VERSION ""

NS_ :

BS_:

BU_: ADAS MINIEYE_TRANSMITTER

BO_ 3221225472 VECTOR__INDEPENDENT_SIG_MSG: 0 Vector__XXX
 SG_ Lane1_CanMsgEnd : 0|1@1+ (1,0) [0|1] "" Vector__XXX
 SG_ Lane2_CanMsgEnd : 0|1@1+ (1,0) [0|1] "" Vector__XXX
 SG_ Lane3_CanMsgEnd : 0|1@1+ (1,0) [0|1] "" Vector__XXX
 SG_ Lane4_CanMsgEnd : 0|1@1+ (1,0) [0|1] "" Vector__XXX

BO_ 1056 DebugMessage: 8 Vector__XXX
 SG_ Speed : 40|8@1+ (1,0) [0|255] "km/h" Vector__XXX
 SG_ Counter : 32|8@1+ (1,0) [0|255] "" Vector__XXX
 SG_ FrameID : 0|32@1+ (1,0) [0|4294967295] "" Vector__XXX

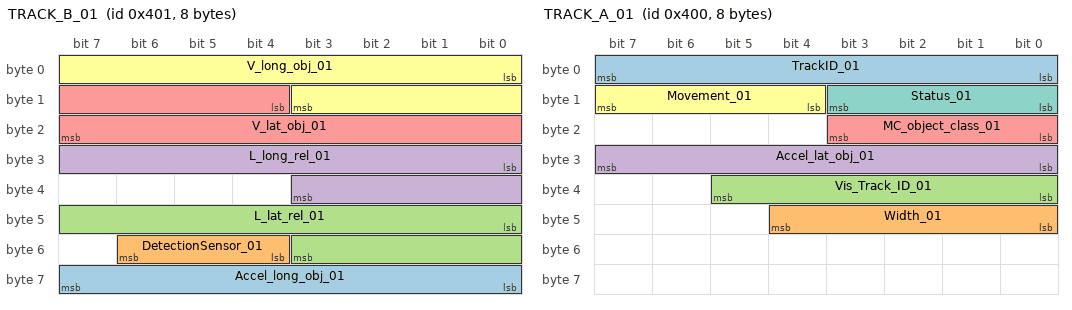
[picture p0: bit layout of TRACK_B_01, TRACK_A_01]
BO_ 1025 TRACK_B_01: 8 MINIEYE_TRANSMITTER
 SG_ Accel_long_obj_01 : 56|8@1- (0.1,0) [-12.5|12.5] "m/s2"  ADAS
 SG_ DetectionSensor_01 : 52|3@1+ (1,0) [0|7] ""  ADAS
 SG_ L_lat_rel_01 : 40|12@1- (0.05,0) [-100|100] "m"  ADAS
 SG_ L_long_rel_01 : 24|12@1- (0.1,0) [0|200] "m"  ADAS
 SG_ V_lat_obj_01 : 12|12@1- (0.1,0) [-50|50] "m/s"  ADAS
 SG_ V_long_obj_01 : 0|12@1- (0.1,0) [-100|100] "m/s"  ADAS

BO_ 1024 TRACK_A_01: 8 MINIEYE_TRANSMITTER
 SG_ TrackID_01 : 0|8@1+ (1,0) [0|63] ""  ADAS
 SG_ Width_01 : 40|5@1+ (0.1,0) [0|3.1] "m"  ADAS
 SG_ Vis_Track_ID_01 : 32|6@1+ (1,0) [0|63] ""  ADAS
 SG_ Accel_lat_obj_01 : 24|8@1- (0.1,0) [-10|10] "m/s2"  ADAS
 SG_ MC_object_class_01 : 16|4@1+ (1,0) [0|10] ""  ADAS
 SG_ Movement_01 : 12|4@1+ (1,0) [0|15] ""  ADAS
 SG_ Status_01 : 8|4@1+ (1,0) [0|7] ""  ADAS

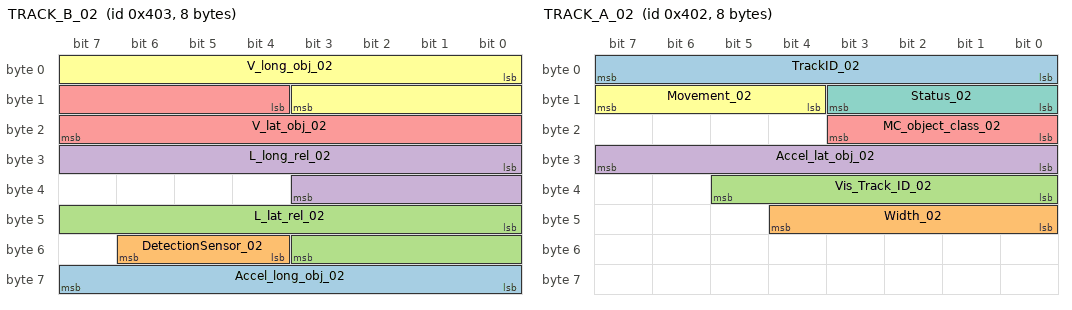
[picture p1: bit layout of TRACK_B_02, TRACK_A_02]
BO_ 1027 TRACK_B_02: 8 MINIEYE_TRANSMITTER
 SG_ Accel_long_obj_02 : 56|8@1- (0.1,0) [-12.5|12.5] "m/s2"  ADAS
 SG_ DetectionSensor_02 : 52|3@1+ (1,0) [0|7] ""  ADAS
 SG_ L_lat_rel_02 : 40|12@1- (0.05,0) [-100|100] "m"  ADAS
 SG_ L_long_rel_02 : 24|12@1- (0.1,0) [0|200] "m"  ADAS
 SG_ V_lat_obj_02 : 12|12@1- (0.1,0) [-50|50] "m/s"  ADAS
 SG_ V_long_obj_02 : 0|12@1- (0.1,0) [-100|100] "m/s"  ADAS

BO_ 1026 TRACK_A_02: 8 MINIEYE_TRANSMITTER
 SG_ TrackID_02 : 0|8@1+ (1,0) [0|63] ""  ADAS
 SG_ Width_02 : 40|5@1+ (0.1,0) [0|3.1] "m"  ADAS
 SG_ Vis_Track_ID_02 : 32|6@1+ (1,0) [0|63] ""  ADAS
 SG_ Accel_lat_obj_02 : 24|8@1- (0.1,0) [-10|10] "m/s2"  ADAS
 SG_ MC_object_class_02 : 16|4@1+ (1,0) [0|10] ""  ADAS
 SG_ Movement_02 : 12|4@1+ (1,0) [0|15] ""  ADAS
 SG_ Status_02 : 8|4@1+ (1,0) [0|7] ""  ADAS

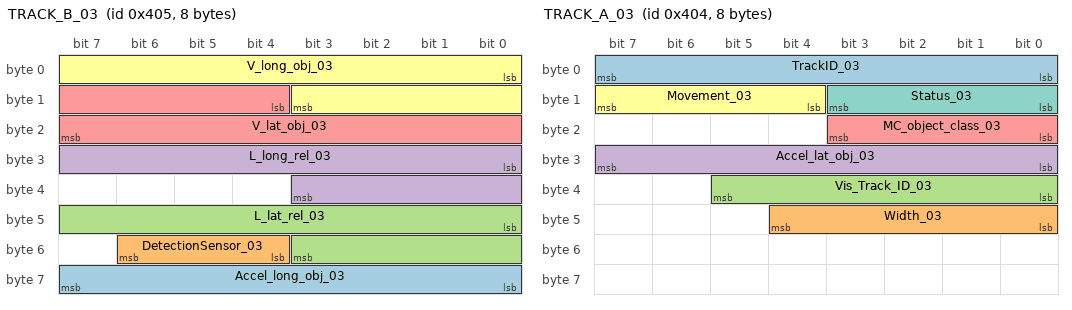
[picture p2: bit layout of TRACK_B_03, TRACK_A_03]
BO_ 1029 TRACK_B_03: 8 MINIEYE_TRANSMITTER
 SG_ Accel_long_obj_03 : 56|8@1- (0.1,0) [-12.5|12.5] "m/s2"  ADAS
 SG_ DetectionSensor_03 : 52|3@1+ (1,0) [0|7] ""  ADAS
 SG_ L_lat_rel_03 : 40|12@1- (0.05,0) [-100|100] "m"  ADAS
 SG_ L_long_rel_03 : 24|12@1- (0.1,0) [0|200] "m"  ADAS
 SG_ V_lat_obj_03 : 12|12@1- (0.1,0) [-50|50] "m/s"  ADAS
 SG_ V_long_obj_03 : 0|12@1- (0.1,0) [-100|100] "m/s"  ADAS

BO_ 1028 TRACK_A_03: 8 MINIEYE_TRANSMITTER
 SG_ TrackID_03 : 0|8@1+ (1,0) [0|63] ""  ADAS
 SG_ Width_03 : 40|5@1+ (0.1,0) [0|3.1] "m"  ADAS
 SG_ Vis_Track_ID_03 : 32|6@1+ (1,0) [0|63] ""  ADAS
 SG_ Accel_lat_obj_03 : 24|8@1- (0.1,0) [-10|10] "m/s2"  ADAS
 SG_ MC_object_class_03 : 16|4@1+ (1,0) [0|10] ""  ADAS
 SG_ Movement_03 : 12|4@1+ (1,0) [0|15] ""  ADAS
 SG_ Status_03 : 8|4@1+ (1,0) [0|7] ""  ADAS

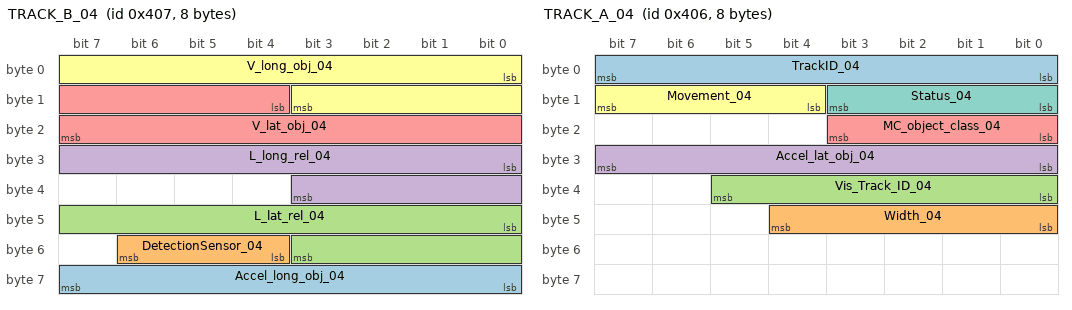
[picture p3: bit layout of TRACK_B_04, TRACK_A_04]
BO_ 1031 TRACK_B_04: 8 MINIEYE_TRANSMITTER
 SG_ Accel_long_obj_04 : 56|8@1- (0.1,0) [-12.5|12.5] "m/s2"  ADAS
 SG_ DetectionSensor_04 : 52|3@1+ (1,0) [0|7] ""  ADAS
 SG_ L_lat_rel_04 : 40|12@1- (0.05,0) [-100|100] "m"  ADAS
 SG_ L_long_rel_04 : 24|12@1- (0.1,0) [0|200] "m"  ADAS
 SG_ V_lat_obj_04 : 12|12@1- (0.1,0) [-50|50] "m/s"  ADAS
 SG_ V_long_obj_04 : 0|12@1- (0.1,0) [-100|100] "m/s"  ADAS

BO_ 1030 TRACK_A_04: 8 MINIEYE_TRANSMITTER
 SG_ TrackID_04 : 0|8@1+ (1,0) [0|63] ""  ADAS
 SG_ Width_04 : 40|5@1+ (0.1,0) [0|3.1] "m"  ADAS
 SG_ Vis_Track_ID_04 : 32|6@1+ (1,0) [0|63] ""  ADAS
 SG_ Accel_lat_obj_04 : 24|8@1- (0.1,0) [-10|10] "m/s2"  ADAS
 SG_ MC_object_class_04 : 16|4@1+ (1,0) [0|10] ""  ADAS
 SG_ Movement_04 : 12|4@1+ (1,0) [0|15] ""  ADAS
 SG_ Status_04 : 8|4@1+ (1,0) [0|7] ""  ADAS

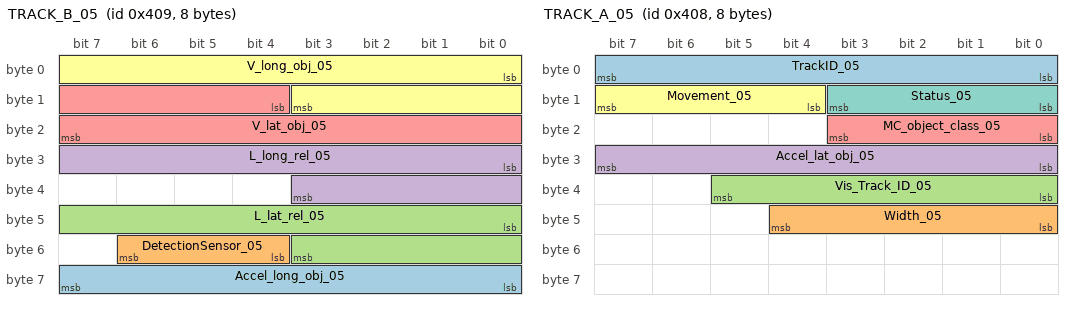
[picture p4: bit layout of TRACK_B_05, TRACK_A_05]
BO_ 1033 TRACK_B_05: 8 MINIEYE_TRANSMITTER
 SG_ Accel_long_obj_05 : 56|8@1- (0.1,0) [-12.5|12.5] "m/s2"  ADAS
 SG_ DetectionSensor_05 : 52|3@1+ (1,0) [0|7] ""  ADAS
 SG_ L_lat_rel_05 : 40|12@1- (0.05,0) [-100|100] "m"  ADAS
 SG_ L_long_rel_05 : 24|12@1- (0.1,0) [0|200] "m"  ADAS
 SG_ V_lat_obj_05 : 12|12@1- (0.1,0) [-50|50] "m/s"  ADAS
 SG_ V_long_obj_05 : 0|12@1- (0.1,0) [-100|100] "m/s"  ADAS

BO_ 1032 TRACK_A_05: 8 MINIEYE_TRANSMITTER
 SG_ TrackID_05 : 0|8@1+ (1,0) [0|63] ""  ADAS
 SG_ Width_05 : 40|5@1+ (0.1,0) [0|3.1] "m"  ADAS
 SG_ Vis_Track_ID_05 : 32|6@1+ (1,0) [0|63] ""  ADAS
 SG_ Accel_lat_obj_05 : 24|8@1- (0.1,0) [-10|10] "m/s2"  ADAS
 SG_ MC_object_class_05 : 16|4@1+ (1,0) [0|10] ""  ADAS
 SG_ Movement_05 : 12|4@1+ (1,0) [0|15] ""  ADAS
 SG_ Status_05 : 8|4@1+ (1,0) [0|7] ""  ADAS

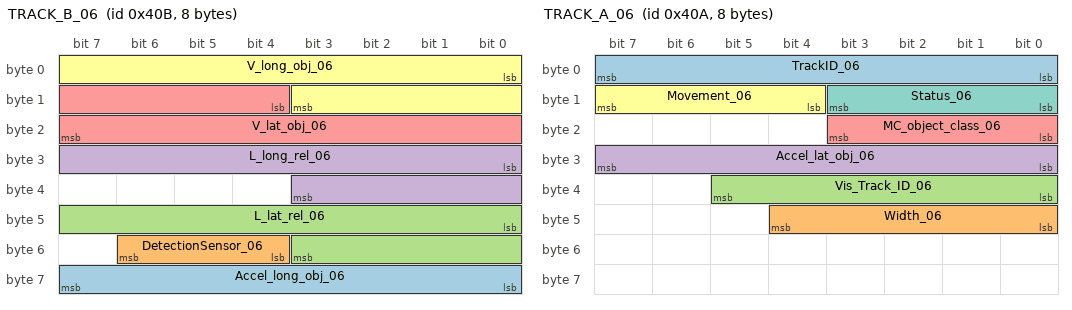
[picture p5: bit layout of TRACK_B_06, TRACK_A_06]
BO_ 1035 TRACK_B_06: 8 MINIEYE_TRANSMITTER
 SG_ Accel_long_obj_06 : 56|8@1- (0.1,0) [-12.5|12.5] "m/s2"  ADAS
 SG_ DetectionSensor_06 : 52|3@1+ (1,0) [0|7] ""  ADAS
 SG_ L_lat_rel_06 : 40|12@1- (0.05,0) [-100|100] "m"  ADAS
 SG_ L_long_rel_06 : 24|12@1- (0.1,0) [0|200] "m"  ADAS
 SG_ V_lat_obj_06 : 12|12@1- (0.1,0) [-50|50] "m/s"  ADAS
 SG_ V_long_obj_06 : 0|12@1- (0.1,0) [-100|100] "m/s"  ADAS

BO_ 1034 TRACK_A_06: 8 MINIEYE_TRANSMITTER
 SG_ TrackID_06 : 0|8@1+ (1,0) [0|63] ""  ADAS
 SG_ Width_06 : 40|5@1+ (0.1,0) [0|3.1] "m"  ADAS
 SG_ Vis_Track_ID_06 : 32|6@1+ (1,0) [0|63] ""  ADAS
 SG_ Accel_lat_obj_06 : 24|8@1- (0.1,0) [-10|10] "m/s2"  ADAS
 SG_ MC_object_class_06 : 16|4@1+ (1,0) [0|10] ""  ADAS
 SG_ Movement_06 : 12|4@1+ (1,0) [0|15] ""  ADAS
 SG_ Status_06 : 8|4@1+ (1,0) [0|7] ""  ADAS

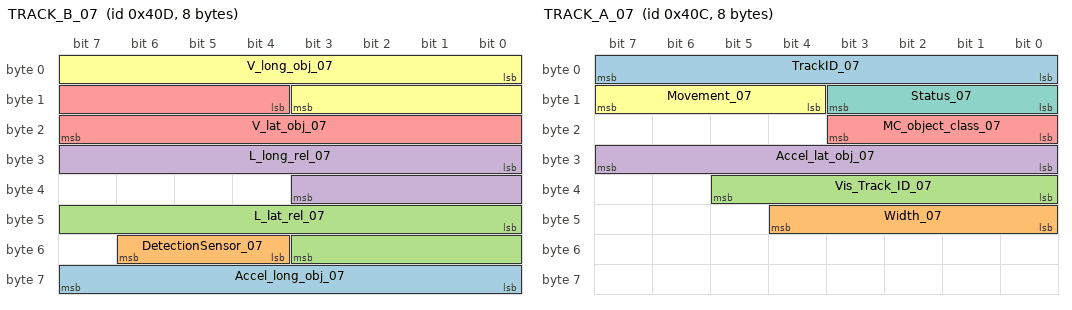
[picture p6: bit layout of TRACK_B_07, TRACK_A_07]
BO_ 1037 TRACK_B_07: 8 MINIEYE_TRANSMITTER
 SG_ Accel_long_obj_07 : 56|8@1- (0.1,0) [-12.5|12.5] "m/s2"  ADAS
 SG_ DetectionSensor_07 : 52|3@1+ (1,0) [0|7] ""  ADAS
 SG_ L_lat_rel_07 : 40|12@1- (0.05,0) [-100|100] "m"  ADAS
 SG_ L_long_rel_07 : 24|12@1- (0.1,0) [0|200] "m"  ADAS
 SG_ V_lat_obj_07 : 12|12@1- (0.1,0) [-50|50] "m/s"  ADAS
 SG_ V_long_obj_07 : 0|12@1- (0.1,0) [-100|100] "m/s"  ADAS

BO_ 1036 TRACK_A_07: 8 MINIEYE_TRANSMITTER
 SG_ TrackID_07 : 0|8@1+ (1,0) [0|63] ""  ADAS
 SG_ Width_07 : 40|5@1+ (0.1,0) [0|3.1] "m"  ADAS
 SG_ Vis_Track_ID_07 : 32|6@1+ (1,0) [0|63] ""  ADAS
 SG_ Accel_lat_obj_07 : 24|8@1- (0.1,0) [-10|10] "m/s2"  ADAS
 SG_ MC_object_class_07 : 16|4@1+ (1,0) [0|10] ""  ADAS
 SG_ Movement_07 : 12|4@1+ (1,0) [0|15] ""  ADAS
 SG_ Status_07 : 8|4@1+ (1,0) [0|7] ""  ADAS

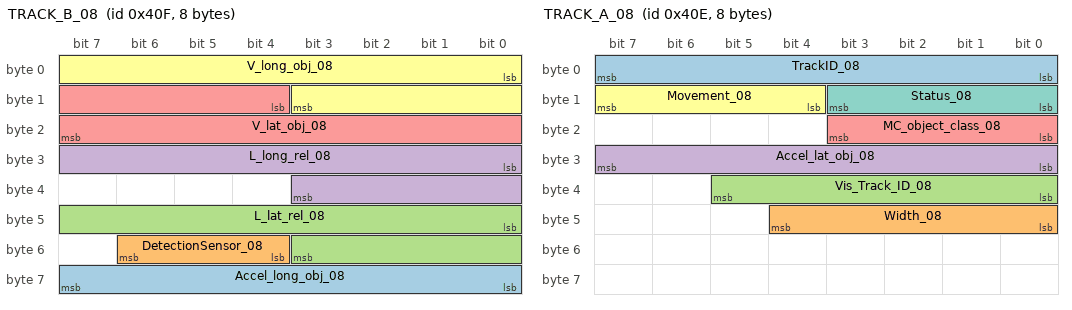
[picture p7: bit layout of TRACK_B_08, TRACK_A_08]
BO_ 1039 TRACK_B_08: 8 MINIEYE_TRANSMITTER
 SG_ Accel_long_obj_08 : 56|8@1- (0.1,0) [-12.5|12.5] "m/s2"  ADAS
 SG_ DetectionSensor_08 : 52|3@1+ (1,0) [0|7] ""  ADAS
 SG_ L_lat_rel_08 : 40|12@1- (0.05,0) [-100|100] "m"  ADAS
 SG_ L_long_rel_08 : 24|12@1- (0.1,0) [0|200] "m"  ADAS
 SG_ V_lat_obj_08 : 12|12@1- (0.1,0) [-50|50] "m/s"  ADAS
 SG_ V_long_obj_08 : 0|12@1- (0.1,0) [-100|100] "m/s"  ADAS

BO_ 1038 TRACK_A_08: 8 MINIEYE_TRANSMITTER
 SG_ TrackID_08 : 0|8@1+ (1,0) [0|63] ""  ADAS
 SG_ Width_08 : 40|5@1+ (0.1,0) [0|3.1] "m"  ADAS
 SG_ Vis_Track_ID_08 : 32|6@1+ (1,0) [0|63] ""  ADAS
 SG_ Accel_lat_obj_08 : 24|8@1- (0.1,0) [-10|10] "m/s2"  ADAS
 SG_ MC_object_class_08 : 16|4@1+ (1,0) [0|10] ""  ADAS
 SG_ Movement_08 : 12|4@1+ (1,0) [0|15] ""  ADAS
 SG_ Status_08 : 8|4@1+ (1,0) [0|7] ""  ADAS

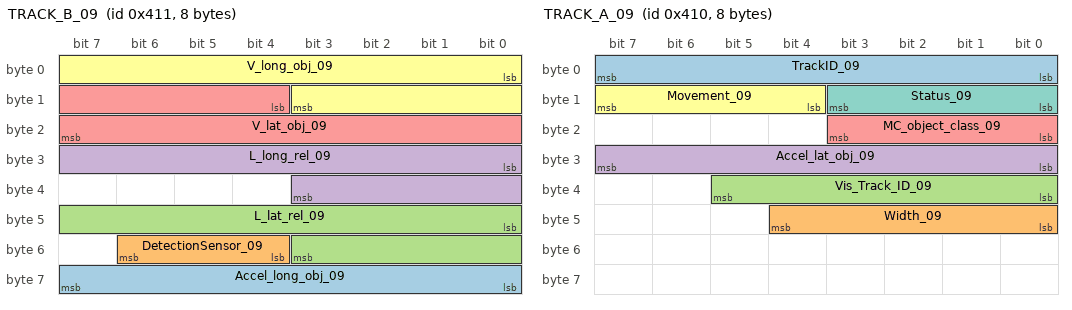
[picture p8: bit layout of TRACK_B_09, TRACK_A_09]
BO_ 1041 TRACK_B_09: 8 MINIEYE_TRANSMITTER
 SG_ Accel_long_obj_09 : 56|8@1- (0.1,0) [-12.5|12.5] "m/s2"  ADAS
 SG_ DetectionSensor_09 : 52|3@1+ (1,0) [0|7] ""  ADAS
 SG_ L_lat_rel_09 : 40|12@1- (0.05,0) [-100|100] "m"  ADAS
 SG_ L_long_rel_09 : 24|12@1- (0.1,0) [0|200] "m"  ADAS
 SG_ V_lat_obj_09 : 12|12@1- (0.1,0) [-50|50] "m/s"  ADAS
 SG_ V_long_obj_09 : 0|12@1- (0.1,0) [-100|100] "m/s"  ADAS

BO_ 1040 TRACK_A_09: 8 MINIEYE_TRANSMITTER
 SG_ TrackID_09 : 0|8@1+ (1,0) [0|63] ""  ADAS
 SG_ Width_09 : 40|5@1+ (0.1,0) [0|3.1] "m"  ADAS
 SG_ Vis_Track_ID_09 : 32|6@1+ (1,0) [0|63] ""  ADAS
 SG_ Accel_lat_obj_09 : 24|8@1- (0.1,0) [-10|10] "m/s2"  ADAS
 SG_ MC_object_class_09 : 16|4@1+ (1,0) [0|10] ""  ADAS
 SG_ Movement_09 : 12|4@1+ (1,0) [0|15] ""  ADAS
 SG_ Status_09 : 8|4@1+ (1,0) [0|7] ""  ADAS

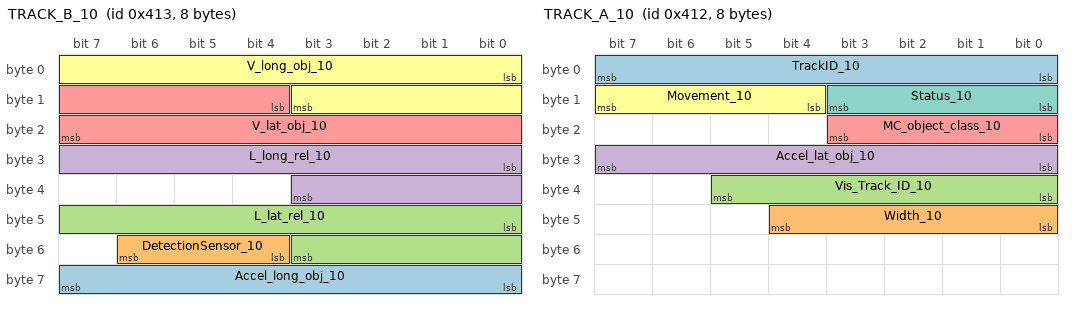
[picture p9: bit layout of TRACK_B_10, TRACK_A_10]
BO_ 1043 TRACK_B_10: 8 MINIEYE_TRANSMITTER
 SG_ Accel_long_obj_10 : 56|8@1- (0.1,0) [-12.5|12.5] "m/s2"  ADAS
 SG_ DetectionSensor_10 : 52|3@1+ (1,0) [0|7] ""  ADAS
 SG_ L_lat_rel_10 : 40|12@1- (0.05,0) [-100|100] "m"  ADAS
 SG_ L_long_rel_10 : 24|12@1- (0.1,0) [0|200] "m"  ADAS
 SG_ V_lat_obj_10 : 12|12@1- (0.1,0) [-50|50] "m/s"  ADAS
 SG_ V_long_obj_10 : 0|12@1- (0.1,0) [-100|100] "m/s"  ADAS

BO_ 1042 TRACK_A_10: 8 MINIEYE_TRANSMITTER
 SG_ TrackID_10 : 0|8@1+ (1,0) [0|63] ""  ADAS
 SG_ Width_10 : 40|5@1+ (0.1,0) [0|3.1] "m"  ADAS
 SG_ Vis_Track_ID_10 : 32|6@1+ (1,0) [0|63] ""  ADAS
 SG_ Accel_lat_obj_10 : 24|8@1- (0.1,0) [-10|10] "m/s2"  ADAS
 SG_ MC_object_class_10 : 16|4@1+ (1,0) [0|10] ""  ADAS
 SG_ Movement_10 : 12|4@1+ (1,0) [0|15] ""  ADAS
 SG_ Status_10 : 8|4@1+ (1,0) [0|7] ""  ADAS

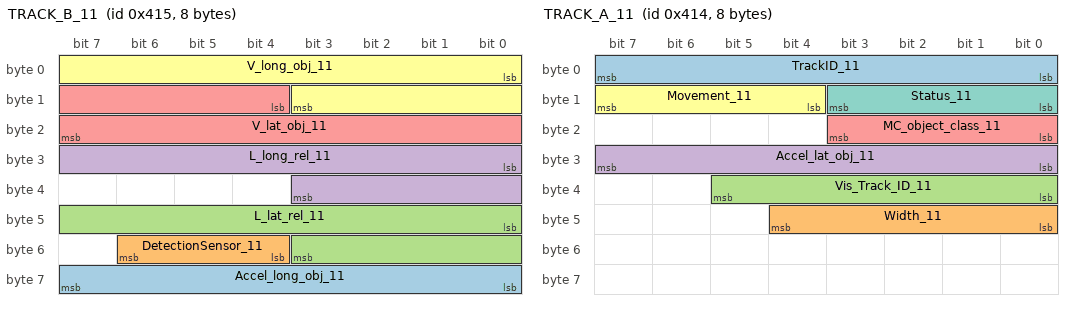
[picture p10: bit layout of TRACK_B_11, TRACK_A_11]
BO_ 1045 TRACK_B_11: 8 MINIEYE_TRANSMITTER
 SG_ Accel_long_obj_11 : 56|8@1- (0.1,0) [-12.5|12.5] "m/s2"  ADAS
 SG_ DetectionSensor_11 : 52|3@1+ (1,0) [0|7] ""  ADAS
 SG_ L_lat_rel_11 : 40|12@1- (0.05,0) [-100|100] "m"  ADAS
 SG_ L_long_rel_11 : 24|12@1- (0.1,0) [0|200] "m"  ADAS
 SG_ V_lat_obj_11 : 12|12@1- (0.1,0) [-50|50] "m/s"  ADAS
 SG_ V_long_obj_11 : 0|12@1- (0.1,0) [-100|100] "m/s"  ADAS

BO_ 1044 TRACK_A_11: 8 MINIEYE_TRANSMITTER
 SG_ TrackID_11 : 0|8@1+ (1,0) [0|63] ""  ADAS
 SG_ Width_11 : 40|5@1+ (0.1,0) [0|3.1] "m"  ADAS
 SG_ Vis_Track_ID_11 : 32|6@1+ (1,0) [0|63] ""  ADAS
 SG_ Accel_lat_obj_11 : 24|8@1- (0.1,0) [-10|10] "m/s2"  ADAS
 SG_ MC_object_class_11 : 16|4@1+ (1,0) [0|10] ""  ADAS
 SG_ Movement_11 : 12|4@1+ (1,0) [0|15] ""  ADAS
 SG_ Status_11 : 8|4@1+ (1,0) [0|7] ""  ADAS

BO_ 1047 TRACK_B_12: 8 MINIEYE_TRANSMITTER
 SG_ Accel_long_obj_12 : 56|8@1- (0.1,0) [-12.5|12.5] "m/s2"  ADAS
 SG_ DetectionSensor_12 : 52|3@1+ (1,0) [0|7] ""  ADAS
 SG_ L_lat_rel_12 : 40|12@1- (0.05,0) [-100|100] "m"  ADAS
 SG_ L_long_rel_12 : 24|12@1- (0.1,0) [0|200] "m"  ADAS
 SG_ V_lat_obj_12 : 12|12@1- (0.1,0) [-50|50] "m/s"  ADAS
 SG_ V_long_obj_12 : 0|12@1- (0.1,0) [-100|100] "m/s"  ADAS

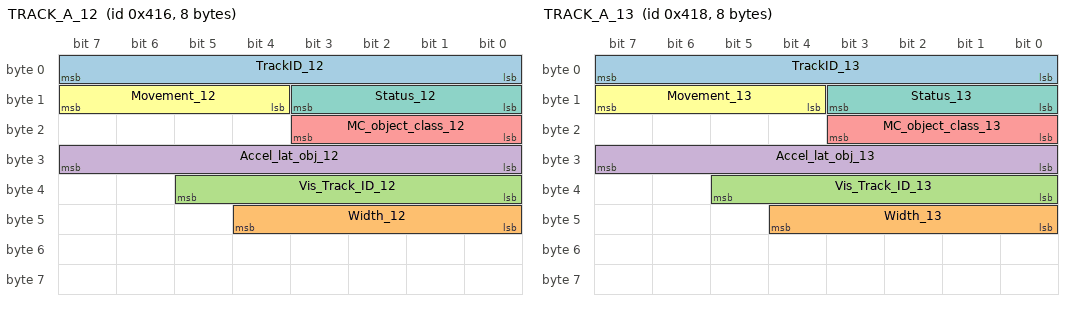
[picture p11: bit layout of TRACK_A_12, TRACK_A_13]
BO_ 1046 TRACK_A_12: 8 MINIEYE_TRANSMITTER
 SG_ TrackID_12 : 0|8@1+ (1,0) [0|63] ""  ADAS
 SG_ Width_12 : 40|5@1+ (0.1,0) [0|3.1] "m"  ADAS
 SG_ Vis_Track_ID_12 : 32|6@1+ (1,0) [0|63] ""  ADAS
 SG_ Accel_lat_obj_12 : 24|8@1- (0.1,0) [-10|10] "m/s2"  ADAS
 SG_ MC_object_class_12 : 16|4@1+ (1,0) [0|10] ""  ADAS
 SG_ Movement_12 : 12|4@1+ (1,0) [0|15] ""  ADAS
 SG_ Status_12 : 8|4@1+ (1,0) [0|7] ""  ADAS

BO_ 1049 TRACK_B_13: 8 MINIEYE_TRANSMITTER
 SG_ Accel_long_obj_13 : 56|8@1- (0.1,0) [-12.5|12.5] "m/s2"  ADAS
 SG_ DetectionSensor_13 : 52|3@1+ (1,0) [0|7] ""  ADAS
 SG_ L_lat_rel_13 : 40|12@1- (0.05,0) [-100|100] "m"  ADAS
 SG_ L_long_rel_13 : 24|12@1- (0.1,0) [0|200] "m"  ADAS
 SG_ V_lat_obj_13 : 12|12@1- (0.1,0) [-50|50] "m/s"  ADAS
 SG_ V_long_obj_13 : 0|12@1- (0.1,0) [-100|100] "m/s"  ADAS

BO_ 1048 TRACK_A_13: 8 MINIEYE_TRANSMITTER
 SG_ TrackID_13 : 0|8@1+ (1,0) [0|63] ""  ADAS
 SG_ Width_13 : 40|5@1+ (0.1,0) [0|3.1] "m"  ADAS
 SG_ Vis_Track_ID_13 : 32|6@1+ (1,0) [0|63] ""  ADAS
 SG_ Accel_lat_obj_13 : 24|8@1- (0.1,0) [-10|10] "m/s2"  ADAS
 SG_ MC_object_class_13 : 16|4@1+ (1,0) [0|10] ""  ADAS
 SG_ Movement_13 : 12|4@1+ (1,0) [0|15] ""  ADAS
 SG_ Status_13 : 8|4@1+ (1,0) [0|7] ""  ADAS

BO_ 1051 TRACK_B_14: 8 MINIEYE_TRANSMITTER
 SG_ Accel_long_obj_14 : 56|8@1- (0.1,0) [-12.5|12.5] "m/s2"  ADAS
 SG_ DetectionSensor_14 : 52|3@1+ (1,0) [0|7] ""  ADAS
 SG_ L_lat_rel_14 : 40|12@1- (0.05,0) [-100|100] "m"  ADAS
 SG_ L_long_rel_14 : 24|12@1- (0.1,0) [0|200] "m"  ADAS
 SG_ V_lat_obj_14 : 12|12@1- (0.1,0) [-50|50] "m/s"  ADAS
 SG_ V_long_obj_14 : 0|12@1- (0.1,0) [-100|100] "m/s"  ADAS

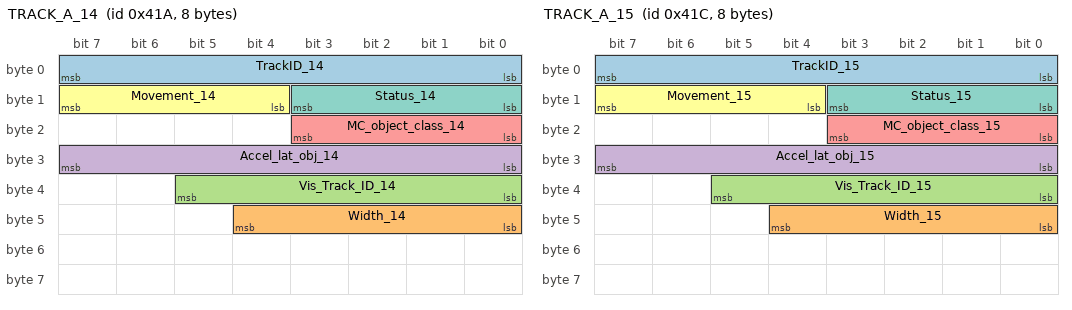
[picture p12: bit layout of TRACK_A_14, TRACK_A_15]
BO_ 1050 TRACK_A_14: 8 MINIEYE_TRANSMITTER
 SG_ TrackID_14 : 0|8@1+ (1,0) [0|63] ""  ADAS
 SG_ Width_14 : 40|5@1+ (0.1,0) [0|3.1] "m"  ADAS
 SG_ Vis_Track_ID_14 : 32|6@1+ (1,0) [0|63] ""  ADAS
 SG_ Accel_lat_obj_14 : 24|8@1- (0.1,0) [-10|10] "m/s2"  ADAS
 SG_ MC_object_class_14 : 16|4@1+ (1,0) [0|10] ""  ADAS
 SG_ Movement_14 : 12|4@1+ (1,0) [0|15] ""  ADAS
 SG_ Status_14 : 8|4@1+ (1,0) [0|7] ""  ADAS

BO_ 1053 TRACK_B_15: 8 MINIEYE_TRANSMITTER
 SG_ Accel_long_obj_15 : 56|8@1- (0.1,0) [-12.5|12.5] "m/s2"  ADAS
 SG_ DetectionSensor_15 : 52|3@1+ (1,0) [0|7] ""  ADAS
 SG_ L_lat_rel_15 : 40|12@1- (0.05,0) [-100|100] "m"  ADAS
 SG_ L_long_rel_15 : 24|12@1- (0.1,0) [0|200] "m"  ADAS
 SG_ V_lat_obj_15 : 12|12@1- (0.1,0) [-50|50] "m/s"  ADAS
 SG_ V_long_obj_15 : 0|12@1- (0.1,0) [-100|100] "m/s"  ADAS

BO_ 1052 TRACK_A_15: 8 MINIEYE_TRANSMITTER
 SG_ TrackID_15 : 0|8@1+ (1,0) [0|63] ""  ADAS
 SG_ Width_15 : 40|5@1+ (0.1,0) [0|3.1] "m"  ADAS
 SG_ Vis_Track_ID_15 : 32|6@1+ (1,0) [0|63] ""  ADAS
 SG_ Accel_lat_obj_15 : 24|8@1- (0.1,0) [-10|10] "m/s2"  ADAS
 SG_ MC_object_class_15 : 16|4@1+ (1,0) [0|10] ""  ADAS
 SG_ Movement_15 : 12|4@1+ (1,0) [0|15] ""  ADAS
 SG_ Status_15 : 8|4@1+ (1,0) [0|7] ""  ADAS

BO_ 1055 TRACK_B_16: 8 MINIEYE_TRANSMITTER
 SG_ Accel_long_obj_16 : 56|8@1- (0.1,0) [-12.5|12.5] "m/s2"  ADAS
 SG_ DetectionSensor_16 : 52|3@1+ (1,0) [0|7] ""  ADAS
 SG_ L_lat_rel_16 : 40|12@1- (0.05,0) [-100|100] "m"  ADAS
 SG_ L_long_rel_16 : 24|12@1- (0.1,0) [0|200] "m"  ADAS
 SG_ V_lat_obj_16 : 12|12@1- (0.1,0) [-50|50] "m/s"  ADAS
 SG_ V_long_obj_16 : 0|12@1- (0.1,0) [-100|100] "m/s"  ADAS

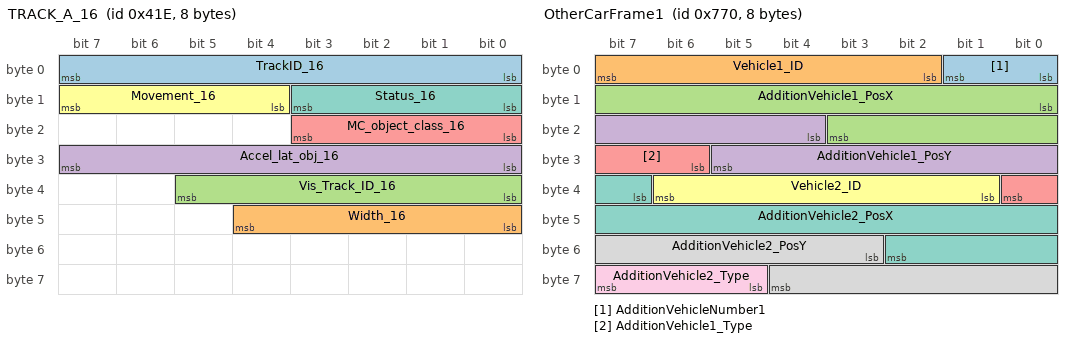
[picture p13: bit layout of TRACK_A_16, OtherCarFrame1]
BO_ 1054 TRACK_A_16: 8 MINIEYE_TRANSMITTER
 SG_ TrackID_16 : 0|8@1+ (1,0) [0|63] ""  ADAS
 SG_ Width_16 : 40|5@1+ (0.1,0) [0|3.1] "m"  ADAS
 SG_ Vis_Track_ID_16 : 32|6@1+ (1,0) [0|63] ""  ADAS
 SG_ Accel_lat_obj_16 : 24|8@1- (0.1,0) [-10|10] "m/s2"  ADAS
 SG_ MC_object_class_16 : 16|4@1+ (1,0) [0|10] ""  ADAS
 SG_ Movement_16 : 12|4@1+ (1,0) [0|15] ""  ADAS
 SG_ Status_16 : 8|4@1+ (1,0) [0|7] ""  ADAS

BO_ 1893 Frameid_TSR: 8 MINIEYE_TRANSMITTER
 SG_ frameid_tsr : 0|32@1+ (1,0) [0|4294967295] ""  ADAS

BO_ 1528 Frameid_Lane: 8 MINIEYE_TRANSMITTER
 SG_ turn_right : 33|1@1+ (1,0) [0|1] ""  ADAS
 SG_ turn_left : 32|1@1+ (1,0) [0|1] ""  ADAS
 SG_ frameid_lane : 0|32@1+ (1,0) [0|4294967295] ""  ADAS

BO_ 1919 Frameid_PED: 8 MINIEYE_TRANSMITTER
 SG_ frameid_ped : 0|32@1+ (1,0) [0|4294967295] ""  ADAS

BO_ 1903 Frameid_Car: 8 MINIEYE_TRANSMITTER
 SG_ speed : 32|8@1+ (1,0) [0|255] "km/h"  ADAS
 SG_ frameid_car : 0|32@1+ (1,0) [0|4294967295] ""  ADAS

BO_ 1901 KeyCarFrameA1: 8 MINIEYE_TRANSMITTER
 SG_ FCW : 0|1@1+ (1,0) [0|1] ""  ADAS
 SG_ Vehicle_ID : 2|6@1+ (1,0) [0|63] ""  ADAS
 SG_ TargetVehicle_PosX : 8|12@1+ (0.0625,0) [0|250] "m"  ADAS
 SG_ TargetVehicle_PosY : 32|10@1- (0.0625,0) [-31.9375|31.9375] "m"  ADAS
 SG_ TargetVehicle_Type : 48|3@1+ (1,0) [0|7] ""  ADAS

BO_ 1902 KeyCarFrameA2: 8 MINIEYE_TRANSMITTER
 SG_ TargetVehicle_TTC : 0|10@1+ (0.01,0) [0|10] "sec"  ADAS
 SG_ TargetVehicle_VelX : 16|12@1- (0.0625,0) [-127.93|127.93] "m/sec"  ADAS
 SG_ TargetVehicle_AccelX : 32|10@1- (0.03,0) [-14.97|14.97] "m/sec^2"  ADAS
 SG_ TargetVehicle_Width : 48|8@1+ (0.05,0) [0|12.5] "M"  ADAS
 SG_ TargetVehicle_Confidence : 56|6@1+ (0.02,0) [0|1] ""  ADAS

BO_ 1904 OtherCarFrame1: 8 MINIEYE_TRANSMITTER
 SG_ AdditionVehicleNumber1 : 0|2@1+ (1,0) [0|2] ""  ADAS
 SG_ Vehicle1_ID : 2|6@1+ (1,0) [0|63] ""  ADAS
 SG_ AdditionVehicle1_PosX : 8|12@1+ (0.0625,0) [0|250] "Meter"  ADAS
 SG_ AdditionVehicle1_PosY : 20|10@1- (0.0625,0) [-31.9375|31.9375] "Meter"  ADAS
 SG_ AdditionVehicle1_Type : 30|3@1+ (1,0) [0|5] ""  ADAS
 SG_ Vehicle2_ID : 33|6@1+ (1,0) [0|63] ""  ADAS
 SG_ AdditionVehicle2_PosX : 39|12@1+ (0.0625,0) [0|250] "Meter"  ADAS
 SG_ AdditionVehicle2_PosY : 51|10@1- (0.0625,0) [-31.9375|31.9375] "Meter"  ADAS
 SG_ AdditionVehicle2_Type : 61|3@1+ (1,0) [0|5] ""  ADAS

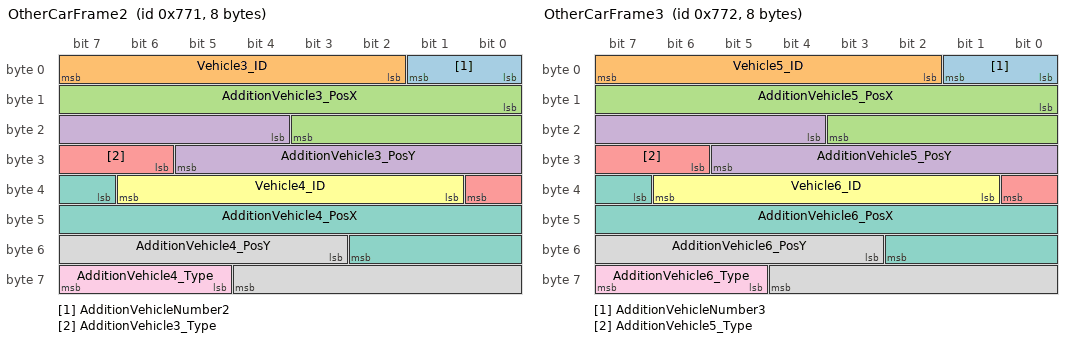
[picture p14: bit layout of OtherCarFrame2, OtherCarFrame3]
BO_ 1905 OtherCarFrame2: 8 MINIEYE_TRANSMITTER
 SG_ AdditionVehicleNumber2 : 0|2@1+ (1,0) [0|2] ""  ADAS
 SG_ Vehicle3_ID : 2|6@1+ (1,0) [0|63] ""  ADAS
 SG_ AdditionVehicle3_PosX : 8|12@1+ (0.0625,0) [0|250] "Meter"  ADAS
 SG_ AdditionVehicle3_PosY : 20|10@1- (0.0625,0) [-31.9375|31.9375] "Meter"  ADAS
 SG_ AdditionVehicle3_Type : 30|3@1+ (1,0) [0|5] ""  ADAS
 SG_ Vehicle4_ID : 33|6@1+ (1,0) [0|63] ""  ADAS
 SG_ AdditionVehicle4_PosX : 39|12@1+ (0.0625,0) [0|250] "Meter"  ADAS
 SG_ AdditionVehicle4_PosY : 51|10@1- (0.0625,0) [-31.9375|31.9375] "Meter"  ADAS
 SG_ AdditionVehicle4_Type : 61|3@1+ (1,0) [0|5] ""  ADAS

BO_ 1906 OtherCarFrame3: 8 MINIEYE_TRANSMITTER
 SG_ AdditionVehicleNumber3 : 0|2@1+ (1,0) [0|2] ""  ADAS
 SG_ Vehicle5_ID : 2|6@1+ (1,0) [0|63] ""  ADAS
 SG_ AdditionVehicle5_PosX : 8|12@1+ (0.0625,0) [0|250] "Meter"  ADAS
 SG_ AdditionVehicle5_PosY : 20|10@1- (0.0625,0) [-31.9375|31.9375] "Meter"  ADAS
 SG_ AdditionVehicle5_Type : 30|3@1+ (1,0) [0|5] ""  ADAS
 SG_ Vehicle6_ID : 33|6@1+ (1,0) [0|63] ""  ADAS
 SG_ AdditionVehicle6_PosX : 39|12@1+ (0.0625,0) [0|250] "Meter"  ADAS
 SG_ AdditionVehicle6_PosY : 51|10@1- (0.0625,0) [-31.9375|31.9375] "Meter"  ADAS
 SG_ AdditionVehicle6_Type : 61|3@1+ (1,0) [0|5] ""  ADAS

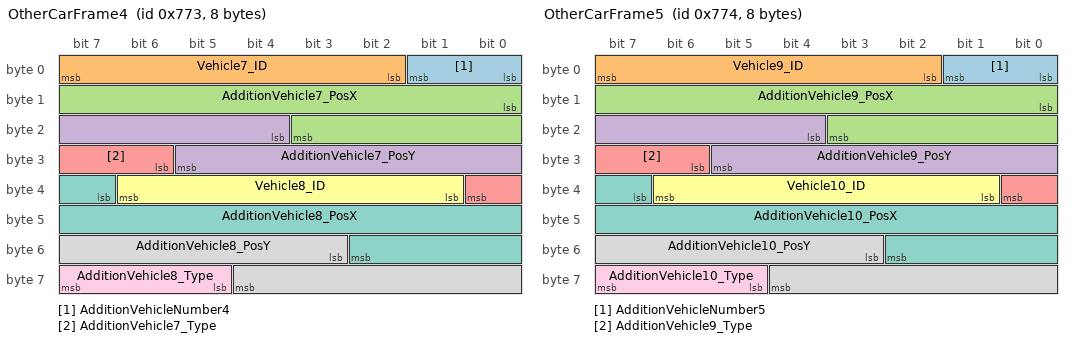
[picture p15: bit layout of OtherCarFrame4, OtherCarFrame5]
BO_ 1907 OtherCarFrame4: 8 MINIEYE_TRANSMITTER
 SG_ AdditionVehicleNumber4 : 0|2@1+ (1,0) [0|2] ""  ADAS
 SG_ Vehicle7_ID : 2|6@1+ (1,0) [0|63] ""  ADAS
 SG_ AdditionVehicle7_PosX : 8|12@1+ (0.0625,0) [0|250] "Meter"  ADAS
 SG_ AdditionVehicle7_PosY : 20|10@1- (0.0625,0) [-31.9375|31.9375] "Meter"  ADAS
 SG_ AdditionVehicle7_Type : 30|3@1+ (1,0) [0|5] ""  ADAS
 SG_ Vehicle8_ID : 33|6@1+ (1,0) [0|63] ""  ADAS
 SG_ AdditionVehicle8_PosX : 39|12@1+ (0.0625,0) [0|250] "Meter"  ADAS
 SG_ AdditionVehicle8_PosY : 51|10@1- (0.0625,0) [-31.9375|31.9375] "Meter"  ADAS
 SG_ AdditionVehicle8_Type : 61|3@1+ (1,0) [0|5] ""  ADAS

BO_ 1908 OtherCarFrame5: 8 MINIEYE_TRANSMITTER
 SG_ AdditionVehicleNumber5 : 0|2@1+ (1,0) [0|2] ""  ADAS
 SG_ Vehicle9_ID : 2|6@1+ (1,0) [0|63] ""  ADAS
 SG_ AdditionVehicle9_PosX : 8|12@1+ (0.0625,0) [0|250] "Meter"  ADAS
 SG_ AdditionVehicle9_PosY : 20|10@1- (0.0625,0) [-31.9375|31.9375] "Meter"  ADAS
 SG_ AdditionVehicle9_Type : 30|3@1+ (1,0) [0|5] ""  ADAS
 SG_ Vehicle10_ID : 33|6@1+ (1,0) [0|63] ""  ADAS
 SG_ AdditionVehicle10_PosX : 39|12@1+ (0.0625,0) [0|250] "Meter"  ADAS
 SG_ AdditionVehicle10_PosY : 51|10@1- (0.0625,0) [-31.9375|31.9375] "Meter"  ADAS
 SG_ AdditionVehicle10_Type : 61|3@1+ (1,0) [0|5] ""  ADAS

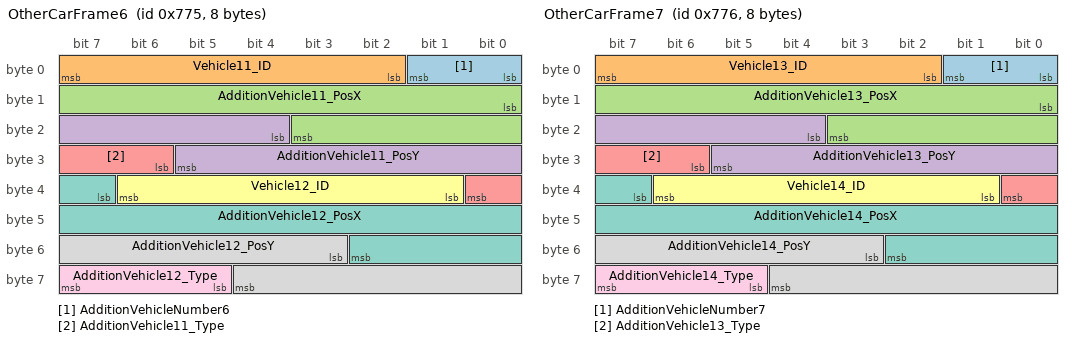
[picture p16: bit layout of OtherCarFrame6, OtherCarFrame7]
BO_ 1909 OtherCarFrame6: 8 MINIEYE_TRANSMITTER
 SG_ AdditionVehicleNumber6 : 0|2@1+ (1,0) [0|2] ""  ADAS
 SG_ Vehicle11_ID : 2|6@1+ (1,0) [0|63] ""  ADAS
 SG_ AdditionVehicle11_PosX : 8|12@1+ (0.0625,0) [0|250] "Meter"  ADAS
 SG_ AdditionVehicle11_PosY : 20|10@1- (0.0625,0) [-31.9375|31.9375] "Meter"  ADAS
 SG_ AdditionVehicle11_Type : 30|3@1+ (1,0) [0|5] ""  ADAS
 SG_ Vehicle12_ID : 33|6@1+ (1,0) [0|63] ""  ADAS
 SG_ AdditionVehicle12_PosX : 39|12@1+ (0.0625,0) [0|250] "Meter"  ADAS
 SG_ AdditionVehicle12_PosY : 51|10@1- (0.0625,0) [-31.9375|31.9375] "Meter"  ADAS
 SG_ AdditionVehicle12_Type : 61|3@1+ (1,0) [0|5] ""  ADAS

BO_ 1910 OtherCarFrame7: 8 MINIEYE_TRANSMITTER
 SG_ AdditionVehicleNumber7 : 0|2@1+ (1,0) [0|2] ""  ADAS
 SG_ Vehicle13_ID : 2|6@1+ (1,0) [0|63] ""  ADAS
 SG_ AdditionVehicle13_PosX : 8|12@1+ (0.0625,0) [0|250] "Meter"  ADAS
 SG_ AdditionVehicle13_PosY : 20|10@1- (0.0625,0) [-31.9375|31.9375] "Meter"  ADAS
 SG_ AdditionVehicle13_Type : 30|3@1+ (1,0) [0|5] ""  ADAS
 SG_ Vehicle14_ID : 33|6@1+ (1,0) [0|63] ""  ADAS
 SG_ AdditionVehicle14_PosX : 39|12@1+ (0.0625,0) [0|250] "Meter"  ADAS
 SG_ AdditionVehicle14_PosY : 51|10@1- (0.0625,0) [-31.9375|31.9375] "Meter"  ADAS
 SG_ AdditionVehicle14_Type : 61|3@1+ (1,0) [0|5] ""  ADAS

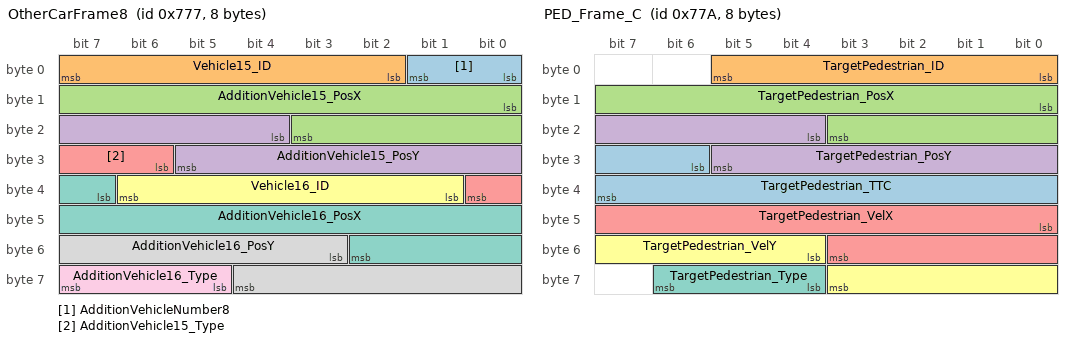
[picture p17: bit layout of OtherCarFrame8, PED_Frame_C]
BO_ 1911 OtherCarFrame8: 8 MINIEYE_TRANSMITTER
 SG_ AdditionVehicleNumber8 : 0|2@1+ (1,0) [0|2] ""  ADAS
 SG_ Vehicle15_ID : 2|6@1+ (1,0) [0|63] ""  ADAS
 SG_ AdditionVehicle15_PosX : 8|12@1+ (0.0625,0) [0|250] "Meter"  ADAS
 SG_ AdditionVehicle15_PosY : 20|10@1- (0.0625,0) [-31.9375|31.9375] "Meter"  ADAS
 SG_ AdditionVehicle15_Type : 30|3@1+ (1,0) [0|5] ""  ADAS
 SG_ Vehicle16_ID : 33|6@1+ (1,0) [0|63] ""  ADAS
 SG_ AdditionVehicle16_PosX : 39|12@1+ (0.0625,0) [0|250] "Meter"  ADAS
 SG_ AdditionVehicle16_PosY : 51|10@1- (0.0625,0) [-31.9375|31.9375] "Meter"  ADAS
 SG_ AdditionVehicle16_Type : 61|3@1+ (1,0) [0|5] ""  ADAS

BO_ 1520 Lane1FrameC: 8 MINIEYE_TRANSMITTER
 SG_ Lane1_Type : 0|4@1+ (1,0) [0|15] ""  ADAS
 SG_ Lane1_Quality : 4|2@1+ (1,0) [0|3] ""  ADAS
 SG_ Lane1_Position : 8|16@1- (0.00390625,0) [-128|128] "Meter"  ADAS
 SG_ Lane1_Curvature : 24|16@1+ (9.76563E-007,-0.031999023438) [-0.031999023438|0.032000032767] "1/Meter"  ADAS
 SG_ Lane1_CurvatureDerivative : 40|16@1+ (3.72529E-009,-0.00012206658721) [-0.00012206658721|0.00012207029294] "1/Meter^2"  ADAS
 SG_ Lane1_WidthMarking : 56|8@1+ (0.01,0) [0|2.55] "Meter"  ADAS

BO_ 1521 Lane1FrameD: 8 MINIEYE_TRANSMITTER
 SG_ Lane1_HeadingAngle : 0|16@1+ (1.08949E-005,-0.357) [-0.357|0.357] "radian"  ADAS
 SG_ Lane1_ViewRangeStart : 16|8@1+ (0.5,0) [0|127.5] ""  ADAS
 SG_ Lane1_ViewRangeEnd : 24|8@1+ (0.5,0) [0|127.5] ""  ADAS
 SG_ Lane1_LineCrossing : 32|1@1+ (1,0) [0|1] ""  ADAS
 SG_ Lane1_LineMarkColor : 33|3@1+ (1,0) [0|1] ""  ADAS

BO_ 1522 Lane2FrameC: 8 MINIEYE_TRANSMITTER
 SG_ Lane2_Type : 0|4@1+ (1,0) [0|15] ""  ADAS
 SG_ Lane2_Quality : 4|2@1+ (1,0) [0|3] ""  ADAS
 SG_ Lane2_Position : 8|16@1- (0.00390625,0) [-128|128] "Meter"  ADAS
 SG_ Lane2_Curvature : 24|16@1+ (9.76563E-007,-0.031999023438) [-0.031999023438|0.032000032767] "1/Meter"  ADAS
 SG_ Lane2_CurvatureDerivative : 40|16@1+ (3.72529E-009,-0.00012206658721) [-0.00012206658721|0.00012207029294] "1/Meter^2"  ADAS
 SG_ Lane2_WidthMarking : 56|8@1+ (0.01,0) [0|2.55] "Meter"  ADAS

BO_ 1523 Lane2FrameD: 8 MINIEYE_TRANSMITTER
 SG_ Lane2_HeadingAngle : 0|16@1+ (1.08949E-005,-0.357) [-0.357|0.357] "radian"  ADAS
 SG_ Lane2_ViewRangeStart : 16|8@1+ (0.5,0) [0|127.5] ""  ADAS
 SG_ Lane2_ViewRangeEnd : 24|8@1+ (0.5,0) [0|127.5] ""  ADAS
 SG_ Lane2_LineCrossing : 32|1@1+ (1,0) [0|1] ""  ADAS
 SG_ Lane2_LineMarkColor : 33|3@1+ (1,0) [0|1] ""  ADAS

BO_ 1524 Lane3FrameC: 8 MINIEYE_TRANSMITTER
 SG_ Lane3_Type : 0|4@1+ (1,0) [0|15] ""  ADAS
 SG_ Lane3_Quality : 4|2@1+ (1,0) [0|3] ""  ADAS
 SG_ Lane3_Position : 8|16@1- (0.00390625,0) [-128|128] "Meter"  ADAS
 SG_ Lane3_Curvature : 24|16@1+ (9.76563E-007,-0.031999023438) [-0.031999023438|0.032000032767] "1/Meter"  ADAS
 SG_ Lane3_CurvatureDerivative : 40|16@1+ (3.72529E-009,-0.00012206658721) [-0.00012206658721|0.00012207029294] "1/Meter^2"  ADAS
 SG_ Lane3_WidthMarking : 56|8@1+ (0.01,0) [0|2.55] "Meter"  ADAS

BO_ 1525 Lane3FrameD: 8 MINIEYE_TRANSMITTER
 SG_ Lane3_HeadingAngle : 0|16@1+ (1.08949E-005,-0.357) [-0.357|0.357] "radian"  ADAS
 SG_ Lane3_ViewRangeStart : 16|8@1+ (0.5,0) [0|127.5] ""  ADAS
 SG_ Lane3_ViewRangeEnd : 24|8@1+ (0.5,0) [0|127.5] ""  ADAS
 SG_ Lane3_LineCrossing : 32|1@1+ (1,0) [0|1] ""  ADAS
 SG_ Lane3_LineMarkColor : 33|3@1+ (1,0) [0|1] ""  ADAS

BO_ 1526 Lane4FrameC: 8 MINIEYE_TRANSMITTER
 SG_ Lane4_Type : 0|4@1+ (1,0) [0|15] ""  ADAS
 SG_ Lane4_Quality : 4|2@1+ (1,0) [0|3] ""  ADAS
 SG_ Lane4_Position : 8|16@1- (0.00390625,0) [-128|128] "Meter"  ADAS
 SG_ Lane4_Curvature : 24|16@1+ (9.76563E-007,-0.031999023438) [-0.031999023438|0.032000032767] "1/Meter"  ADAS
 SG_ Lane4_CurvatureDerivative : 40|16@1+ (3.72529E-009,-0.00012206658721) [-0.00012206658721|0.00012207029294] "1/Meter^2"  ADAS
 SG_ Lane4_WidthMarking : 56|8@1+ (0.01,0) [0|2.55] "Meter"  ADAS

BO_ 1527 Lane4FrameD: 8 MINIEYE_TRANSMITTER
 SG_ Lane4_HeadingAngle : 0|16@1+ (1.08949E-005,-0.357) [-0.357|0.357] "radian"  ADAS
 SG_ Lane4_ViewRangeStart : 16|8@1+ (0.5,0) [0|127.5] ""  ADAS
 SG_ Lane4_ViewRangeEnd : 24|8@1+ (0.5,0) [0|127.5] ""  ADAS
 SG_ Lane4_LineCrossing : 32|1@1+ (1,0) [0|1] ""  ADAS
 SG_ Lane4_LineMarkColor : 33|3@1+ (1,0) [0|1] ""  ADAS

BO_ 1914 PED_Frame_C: 8 MINIEYE_TRANSMITTER
 SG_ TargetPedestrian_TTC : 30|10@1+ (0.01,0) [0|10] "s"  ADAS
 SG_ TargetPedestrian_ID : 0|6@1+ (1,0) [0|63] ""  ADAS
 SG_ TargetPedestrian_PosX : 8|12@1+ (0.0625,0) [0|250] "m"  ADAS
 SG_ TargetPedestrian_PosY : 20|10@1- (0.0625,0) [-32|31.9375] "m"  ADAS
 SG_ TargetPedestrian_VelX : 40|12@1- (0.0625,0) [-127.93|127.93] "m/sec"  ADAS
 SG_ TargetPedestrian_VelY : 52|8@1- (0.0625,0) [-8|7.9375] "m/sec"  ADAS
 SG_ TargetPedestrian_Type : 60|3@1+ (1,0) [0|7] ""  ADAS

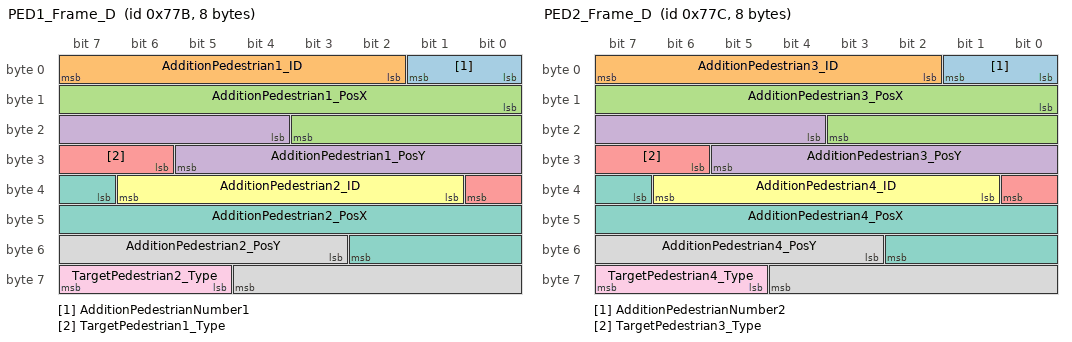
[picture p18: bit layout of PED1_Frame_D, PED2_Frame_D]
BO_ 1915 PED1_Frame_D: 8 MINIEYE_TRANSMITTER
 SG_ AdditionPedestrianNumber1 : 0|2@1+ (1,0) [0|2] ""  ADAS
 SG_ AdditionPedestrian1_ID : 2|6@1+ (1,0) [0|63] ""  ADAS
 SG_ AdditionPedestrian1_PosX : 8|12@1+ (0.0625,0) [0|250] "m"  ADAS
 SG_ AdditionPedestrian1_PosY : 20|10@1- (0.0625,0) [-32|31.9375] "m"  ADAS
 SG_ TargetPedestrian1_Type : 30|3@1+ (1,0) [0|7] ""  ADAS
 SG_ AdditionPedestrian2_ID : 33|6@1+ (1,0) [0|63] ""  ADAS
 SG_ AdditionPedestrian2_PosX : 39|12@1+ (0.0625,0) [0|250] "m"  ADAS
 SG_ AdditionPedestrian2_PosY : 51|10@1- (0.0625,0) [-32|31.9375] "m"  ADAS
 SG_ TargetPedestrian2_Type : 61|3@1+ (1,0) [0|7] ""  ADAS

BO_ 1916 PED2_Frame_D: 8 MINIEYE_TRANSMITTER
 SG_ AdditionPedestrianNumber2 : 0|2@1+ (1,0) [0|2] ""  ADAS
 SG_ AdditionPedestrian3_ID : 2|6@1+ (1,0) [0|63] ""  ADAS
 SG_ AdditionPedestrian3_PosX : 8|12@1+ (0.0625,0) [0|250] "m"  ADAS
 SG_ AdditionPedestrian3_PosY : 20|10@1- (0.0625,0) [-32|31.9375] "m"  ADAS
 SG_ TargetPedestrian3_Type : 30|3@1+ (1,0) [0|7] ""  ADAS
 SG_ AdditionPedestrian4_ID : 33|6@1+ (1,0) [0|63] ""  ADAS
 SG_ AdditionPedestrian4_PosX : 39|12@1+ (0.0625,0) [0|250] "m"  ADAS
 SG_ AdditionPedestrian4_PosY : 51|10@1- (0.0625,0) [-32|31.9375] "m"  ADAS
 SG_ TargetPedestrian4_Type : 61|3@1+ (1,0) [0|7] ""  ADAS

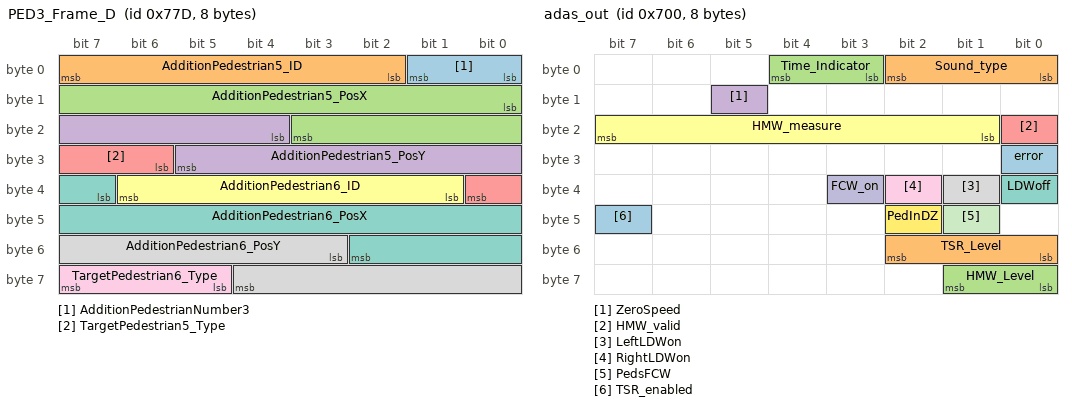
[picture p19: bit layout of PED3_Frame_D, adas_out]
BO_ 1917 PED3_Frame_D: 8 MINIEYE_TRANSMITTER
 SG_ AdditionPedestrianNumber3 : 0|2@1+ (1,0) [0|2] ""  ADAS
 SG_ AdditionPedestrian5_ID : 2|6@1+ (1,0) [0|63] ""  ADAS
 SG_ AdditionPedestrian5_PosX : 8|12@1+ (0.0625,0) [0|250] "m"  ADAS
 SG_ AdditionPedestrian5_PosY : 20|10@1- (0.0625,0) [-32|31.9375] "m"  ADAS
 SG_ TargetPedestrian5_Type : 30|3@1+ (1,0) [0|7] ""  ADAS
 SG_ AdditionPedestrian6_ID : 33|6@1+ (1,0) [0|63] ""  ADAS
 SG_ AdditionPedestrian6_PosX : 39|12@1+ (0.0625,0) [0|250] "m"  ADAS
 SG_ AdditionPedestrian6_PosY : 51|10@1- (0.0625,0) [-32|31.9375] "m"  ADAS
 SG_ TargetPedestrian6_Type : 61|3@1+ (1,0) [0|7] ""  ADAS

BO_ 1889 TSR_A: 8 MINIEYE_TRANSMITTER
 SG_ Vision_only_Sign2_Type : 32|8@1+ (1,0) [0|255] "km/h"  ADAS
 SG_ Vision_only_Sign1_Type : 0|8@1+ (1,0) [0|255] "km/h"  ADAS

BO_ 1890 TSR_B_1: 8 MINIEYE_TRANSMITTER
 SG_ Vision_only_Sign3_Type : 0|8@1+ (1,0) [0|255] "km/h"  ADAS
 SG_ Can_Msg1_Ender : 32|1@1+ (1,0) [0|1] ""  ADAS

BO_ 1891 TSR_B_2: 8 MINIEYE_TRANSMITTER
 SG_ Vision_only_Sign4_Type : 0|8@1+ (1,0) [0|255] "km/h"  ADAS
 SG_ Can_Msg2_Ender : 32|1@1+ (1,0) [0|1] ""  ADAS

BO_ 1892 TSR_B_3: 8 MINIEYE_TRANSMITTER
 SG_ Vision_only_Sign5_Type : 0|8@1+ (1,0) [0|255] "km/h"  ADAS
 SG_ Can_Msg3_Ender : 32|1@1+ (1,0) [0|1] ""  ADAS

BO_ 1792 adas_out: 8 MINIEYE_TRANSMITTER
 SG_ error : 24|1@1+ (1,0) [0|1] ""  ADAS
 SG_ Sound_type : 0|3@1+ (1,0) [0|7] ""  ADAS
 SG_ Time_Indicator : 3|2@1+ (1,0) [0|3] ""  ADAS
 SG_ ZeroSpeed : 13|1@1+ (1,0) [0|1] ""  ADAS
 SG_ HMW_valid : 16|1@1+ (1,0) [0|1] ""  ADAS
 SG_ HMW_measure : 17|7@1+ (0.1,0) [0|9.9] "s"  ADAS
 SG_ LDWoff : 32|1@1+ (1,0) [0|1] ""  ADAS
 SG_ LeftLDWon : 33|1@1+ (1,0) [0|1] ""  ADAS
 SG_ RightLDWon : 34|1@1+ (1,0) [0|1] ""  ADAS
 SG_ FCW_on : 35|1@1+ (1,0) [0|1] ""  ADAS
 SG_ PedsFCW : 41|1@1+ (1,0) [0|1] ""  ADAS
 SG_ PedInDZ : 42|1@1+ (1,0) [0|1] ""  ADAS
 SG_ TSR_enabled : 47|1@1+ (1,0) [0|1] ""  ADAS
 SG_ TSR_Level : 48|3@1+ (1,0) [0|7] ""  ADAS
 SG_ HMW_Level : 56|2@1+ (1,0) [0|3] ""  ADAS

CM_ BO_ 3221225472 "This is a message for not used signals, created by Vector CANdb++ DBC OLE DB Provider.";
BA_DEF_ BO_  "GenMsgSendType" ENUM  "cyclic","spontaneous","cyclicIfActive","spontaneousWithDelay","immediate";
BA_DEF_ BO_  "GenMsgCycleTime" INT 2 50000;
BA_DEF_DEF_  "GenMsgSendType" "cyclic";
BA_DEF_DEF_  "GenMsgCycleTime" 50;
BA_ "GenMsgCycleTime" BO_ 1056 20;
BA_ "GenMsgCycleTime" BO_ 1025 20;
BA_ "GenMsgCycleTime" BO_ 1024 20;
BA_ "GenMsgCycleTime" BO_ 1027 20;
BA_ "GenMsgCycleTime" BO_ 1026 20;
BA_ "GenMsgCycleTime" BO_ 1029 20;
BA_ "GenMsgCycleTime" BO_ 1028 20;
BA_ "GenMsgCycleTime" BO_ 1031 20;
BA_ "GenMsgCycleTime" BO_ 1030 20;
BA_ "GenMsgCycleTime" BO_ 1033 20;
BA_ "GenMsgCycleTime" BO_ 1032 20;
BA_ "GenMsgCycleTime" BO_ 1035 20;
BA_ "GenMsgCycleTime" BO_ 1034 20;
BA_ "GenMsgCycleTime" BO_ 1037 20;
BA_ "GenMsgCycleTime" BO_ 1036 20;
BA_ "GenMsgCycleTime" BO_ 1039 20;
BA_ "GenMsgCycleTime" BO_ 1038 20;
BA_ "GenMsgCycleTime" BO_ 1041 20;
BA_ "GenMsgCycleTime" BO_ 1040 20;
BA_ "GenMsgCycleTime" BO_ 1043 20;
BA_ "GenMsgCycleTime" BO_ 1042 20;
BA_ "GenMsgCycleTime" BO_ 1045 20;
BA_ "GenMsgCycleTime" BO_ 1044 20;
BA_ "GenMsgCycleTime" BO_ 1047 20;
BA_ "GenMsgCycleTime" BO_ 1046 20;
BA_ "GenMsgCycleTime" BO_ 1049 20;
BA_ "GenMsgCycleTime" BO_ 1048 20;
BA_ "GenMsgCycleTime" BO_ 1051 20;
BA_ "GenMsgCycleTime" BO_ 1050 20;
BA_ "GenMsgCycleTime" BO_ 1053 20;
BA_ "GenMsgCycleTime" BO_ 1052 20;
BA_ "GenMsgCycleTime" BO_ 1055 20;
BA_ "GenMsgCycleTime" BO_ 1054 20;
BA_ "GenMsgCycleTime" BO_ 1893 100;
BA_ "GenMsgCycleTime" BO_ 1528 40;
BA_ "GenMsgCycleTime" BO_ 1919 20;
BA_ "GenMsgCycleTime" BO_ 1903 20;
BA_ "GenMsgCycleTime" BO_ 1901 20;
BA_ "GenMsgCycleTime" BO_ 1902 20;
BA_ "GenMsgCycleTime" BO_ 1904 20;
BA_ "GenMsgCycleTime" BO_ 1905 20;
BA_ "GenMsgCycleTime" BO_ 1906 20;
BA_ "GenMsgCycleTime" BO_ 1907 20;
BA_ "GenMsgCycleTime" BO_ 1908 20;
BA_ "GenMsgCycleTime" BO_ 1909 20;
BA_ "GenMsgCycleTime" BO_ 1910 20;
BA_ "GenMsgCycleTime" BO_ 1911 20;
BA_ "GenMsgCycleTime" BO_ 1520 40;
BA_ "GenMsgCycleTime" BO_ 1521 40;
BA_ "GenMsgCycleTime" BO_ 1522 40;
BA_ "GenMsgCycleTime" BO_ 1523 40;
BA_ "GenMsgCycleTime" BO_ 1524 40;
BA_ "GenMsgCycleTime" BO_ 1525 40;
BA_ "GenMsgCycleTime" BO_ 1526 40;
BA_ "GenMsgCycleTime" BO_ 1527 40;
BA_ "GenMsgCycleTime" BO_ 1914 20;
BA_ "GenMsgCycleTime" BO_ 1915 20;
BA_ "GenMsgCycleTime" BO_ 1916 20;
BA_ "GenMsgCycleTime" BO_ 1917 20;
BA_ "GenMsgCycleTime" BO_ 1889 100;
BA_ "GenMsgCycleTime" BO_ 1890 100;
BA_ "GenMsgCycleTime" BO_ 1891 100;
BA_ "GenMsgCycleTime" BO_ 1892 100;
BA_ "GenMsgCycleTime" BO_ 1792 100;
VAL_ 3221225472 Lane1_CanMsgEnd 1 "Finish" 0 "No finish" ;
VAL_ 3221225472 Lane2_CanMsgEnd 1 "Finish" 0 "No finish" ;
VAL_ 3221225472 Lane3_CanMsgEnd 1 "Finish" 0 "No finish" ;
VAL_ 3221225472 Lane4_CanMsgEnd 1 "Finish" 0 "No finish" ;
VAL_ 1025 DetectionSensor_01 4 "tracklets and vision" 3 "vision only" 2 "multiple tracklets" 1 "single tracklet" 0 "no matched measurements" ;
VAL_ 1024 MC_object_class_01 7 "Bicycle" 6 "Pedestrian" 5 "Special car" 4 "Box Truck" 3 "Bus" 2 "Motorcycle" 1 "Car" 0 "Undetermined" ;
VAL_ 1024 Movement_01 15 "NotAvailable" 14 "Error" 13 "Reserved" 12 "Reserved" 11 "NoTrack" 10 "Reserved" 9 "Reserved" 8 "Reserved" 7 "Reserved" 6 "Reserved" 5 "Reserved" 4 "TrackStoppedFromOncoming" 3 "TrackOncoming" 2 "TrackMoving" 1 "TrackStopppedFromMoving" 0 "Stationary" ;
VAL_ 1024 Status_01 7 "Reserved" 6 "Coasted" 5 "Updated" 4 "NewUpdated" 3 "NewCoasted" 2 "New" 1 "Merged" 0 "Invalid" ;
VAL_ 1027 DetectionSensor_02 4 "tracklets and vision" 3 "vision only" 2 "multiple tracklets" 1 "single tracklet" 0 "no matched measurements" ;
VAL_ 1026 MC_object_class_02 7 "Bicycle" 6 "Pedestrian" 5 "Special car" 4 "Box Truck" 3 "Bus" 2 "Motorcycle" 1 "Car" 0 "Undetermined" ;
VAL_ 1026 Movement_02 15 "NotAvailable" 14 "Error" 13 "Reserved" 12 "Reserved" 11 "NoTrack" 10 "Reserved" 9 "Reserved" 8 "Reserved" 7 "Reserved" 6 "Reserved" 5 "Reserved" 4 "TrackStoppedFromOncoming" 3 "TrackOncoming" 2 "TrackMoving" 1 "TrackStopppedFromMoving" 0 "Stationary" ;
VAL_ 1026 Status_02 7 "Reserved" 6 "Coasted" 5 "Updated" 4 "NewUpdated" 3 "NewCoasted" 2 "New" 1 "Merged" 0 "Invalid" ;
VAL_ 1029 DetectionSensor_03 4 "tracklets and vision" 3 "vision only" 2 "multiple tracklets" 1 "single tracklet" 0 "no matched measurements" ;
VAL_ 1028 MC_object_class_03 7 "Bicycle" 6 "Pedestrian" 5 "Special car" 4 "Box Truck" 3 "Bus" 2 "Motorcycle" 1 "Car" 0 "Undetermined" ;
VAL_ 1028 Movement_03 15 "NotAvailable" 14 "Error" 13 "Reserved" 12 "Reserved" 11 "NoTrack" 10 "Reserved" 9 "Reserved" 8 "Reserved" 7 "Reserved" 6 "Reserved" 5 "Reserved" 4 "TrackStoppedFromOncoming" 3 "TrackOncoming" 2 "TrackMoving" 1 "TrackStopppedFromMoving" 0 "Stationary" ;
VAL_ 1028 Status_03 7 "Reserved" 6 "Coasted" 5 "Updated" 4 "NewUpdated" 3 "NewCoasted" 2 "New" 1 "Merged" 0 "Invalid" ;
VAL_ 1031 DetectionSensor_04 4 "tracklets and vision" 3 "vision only" 2 "multiple tracklets" 1 "single tracklet" 0 "no matched measurements" ;
VAL_ 1030 MC_object_class_04 7 "Bicycle" 6 "Pedestrian" 5 "Special car" 4 "Box Truck" 3 "Bus" 2 "Motorcycle" 1 "Car" 0 "Undetermined" ;
VAL_ 1030 Movement_04 15 "NotAvailable" 14 "Error" 13 "Reserved" 12 "Reserved" 11 "NoTrack" 10 "Reserved" 9 "Reserved" 8 "Reserved" 7 "Reserved" 6 "Reserved" 5 "Reserved" 4 "TrackStoppedFromOncoming" 3 "TrackOncoming" 2 "TrackMoving" 1 "TrackStopppedFromMoving" 0 "Stationary" ;
VAL_ 1030 Status_04 7 "Reserved" 6 "Coasted" 5 "Updated" 4 "NewUpdated" 3 "NewCoasted" 2 "New" 1 "Merged" 0 "Invalid" ;
VAL_ 1033 DetectionSensor_05 4 "tracklets and vision" 3 "vision only" 2 "multiple tracklets" 1 "single tracklet" 0 "no matched measurements" ;
VAL_ 1032 MC_object_class_05 7 "Bicycle" 6 "Pedestrian" 5 "Special car" 4 "Box Truck" 3 "Bus" 2 "Motorcycle" 1 "Car" 0 "Undetermined" ;
VAL_ 1032 Movement_05 15 "NotAvailable" 14 "Error" 13 "Reserved" 12 "Reserved" 11 "NoTrack" 10 "Reserved" 9 "Reserved" 8 "Reserved" 7 "Reserved" 6 "Reserved" 5 "Reserved" 4 "TrackStoppedFromOncoming" 3 "TrackOncoming" 2 "TrackMoving" 1 "TrackStopppedFromMoving" 0 "Stationary" ;
VAL_ 1032 Status_05 7 "Reserved" 6 "Coasted" 5 "Updated" 4 "NewUpdated" 3 "NewCoasted" 2 "New" 1 "Merged" 0 "Invalid" ;
VAL_ 1035 DetectionSensor_06 4 "tracklets and vision" 3 "vision only" 2 "multiple tracklets" 1 "single tracklet" 0 "no matched measurements" ;
VAL_ 1034 MC_object_class_06 7 "Bicycle" 6 "Pedestrian" 5 "Special car" 4 "Box Truck" 3 "Bus" 2 "Motorcycle" 1 "Car" 0 "Undetermined" ;
VAL_ 1034 Movement_06 15 "NotAvailable" 14 "Error" 13 "Reserved" 12 "Reserved" 11 "NoTrack" 10 "Reserved" 9 "Reserved" 8 "Reserved" 7 "Reserved" 6 "Reserved" 5 "Reserved" 4 "TrackStoppedFromOncoming" 3 "TrackOncoming" 2 "TrackMoving" 1 "TrackStopppedFromMoving" 0 "Stationary" ;
VAL_ 1034 Status_06 7 "Reserved" 6 "Coasted" 5 "Updated" 4 "NewUpdated" 3 "NewCoasted" 2 "New" 1 "Merged" 0 "Invalid" ;
VAL_ 1037 DetectionSensor_07 4 "tracklets and vision" 3 "vision only" 2 "multiple tracklets" 1 "single tracklet" 0 "no matched measurements" ;
VAL_ 1036 MC_object_class_07 7 "Bicycle" 6 "Pedestrian" 5 "Special car" 4 "Box Truck" 3 "Bus" 2 "Motorcycle" 1 "Car" 0 "Undetermined" ;
VAL_ 1036 Movement_07 15 "NotAvailable" 14 "Error" 13 "Reserved" 12 "Reserved" 11 "NoTrack" 10 "Reserved" 9 "Reserved" 8 "Reserved" 7 "Reserved" 6 "Reserved" 5 "Reserved" 4 "TrackStoppedFromOncoming" 3 "TrackOncoming" 2 "TrackMoving" 1 "TrackStopppedFromMoving" 0 "Stationary" ;
VAL_ 1036 Status_07 7 "Reserved" 6 "Coasted" 5 "Updated" 4 "NewUpdated" 3 "NewCoasted" 2 "New" 1 "Merged" 0 "Invalid" ;
VAL_ 1039 DetectionSensor_08 4 "tracklets and vision" 3 "vision only" 2 "multiple tracklets" 1 "single tracklet" 0 "no matched measurements" ;
VAL_ 1038 MC_object_class_08 7 "Bicycle" 6 "Pedestrian" 5 "Special car" 4 "Box Truck" 3 "Bus" 2 "Motorcycle" 1 "Car" 0 "Undetermined" ;
VAL_ 1038 Movement_08 15 "NotAvailable" 14 "Error" 13 "Reserved" 12 "Reserved" 11 "NoTrack" 10 "Reserved" 9 "Reserved" 8 "Reserved" 7 "Reserved" 6 "Reserved" 5 "Reserved" 4 "TrackStoppedFromOncoming" 3 "TrackOncoming" 2 "TrackMoving" 1 "TrackStopppedFromMoving" 0 "Stationary" ;
VAL_ 1038 Status_08 7 "Reserved" 6 "Coasted" 5 "Updated" 4 "NewUpdated" 3 "NewCoasted" 2 "New" 1 "Merged" 0 "Invalid" ;
VAL_ 1041 DetectionSensor_09 4 "tracklets and vision" 3 "vision only" 2 "multiple tracklets" 1 "single tracklet" 0 "no matched measurements" ;
VAL_ 1040 MC_object_class_09 7 "Bicycle" 6 "Pedestrian" 5 "Special car" 4 "Box Truck" 3 "Bus" 2 "Motorcycle" 1 "Car" 0 "Undetermined" ;
VAL_ 1040 Movement_09 15 "NotAvailable" 14 "Error" 13 "Reserved" 12 "Reserved" 11 "NoTrack" 10 "Reserved" 9 "Reserved" 8 "Reserved" 7 "Reserved" 6 "Reserved" 5 "Reserved" 4 "TrackStoppedFromOncoming" 3 "TrackOncoming" 2 "TrackMoving" 1 "TrackStopppedFromMoving" 0 "Stationary" ;
VAL_ 1040 Status_09 7 "Reserved" 6 "Coasted" 5 "Updated" 4 "NewUpdated" 3 "NewCoasted" 2 "New" 1 "Merged" 0 "Invalid" ;
VAL_ 1043 DetectionSensor_10 4 "tracklets and vision" 3 "vision only" 2 "multiple tracklets" 1 "single tracklet" 0 "no matched measurements" ;
VAL_ 1042 MC_object_class_10 7 "Bicycle" 6 "Pedestrian" 5 "Special car" 4 "Box Truck" 3 "Bus" 2 "Motorcycle" 1 "Car" 0 "Undetermined" ;
VAL_ 1042 Movement_10 15 "NotAvailable" 14 "Error" 13 "Reserved" 12 "Reserved" 11 "NoTrack" 10 "Reserved" 9 "Reserved" 8 "Reserved" 7 "Reserved" 6 "Reserved" 5 "Reserved" 4 "TrackStoppedFromOncoming" 3 "TrackOncoming" 2 "TrackMoving" 1 "TrackStopppedFromMoving" 0 "Stationary" ;
VAL_ 1042 Status_10 7 "Reserved" 6 "Coasted" 5 "Updated" 4 "NewUpdated" 3 "NewCoasted" 2 "New" 1 "Merged" 0 "Invalid" ;
VAL_ 1045 DetectionSensor_11 4 "tracklets and vision" 3 "vision only" 2 "multiple tracklets" 1 "single tracklet" 0 "no matched measurements" ;
VAL_ 1044 MC_object_class_11 7 "Bicycle" 6 "Pedestrian" 5 "Special car" 4 "Box Truck" 3 "Bus" 2 "Motorcycle" 1 "Car" 0 "Undetermined" ;
VAL_ 1044 Movement_11 15 "NotAvailable" 14 "Error" 13 "Reserved" 12 "Reserved" 11 "NoTrack" 10 "Reserved" 9 "Reserved" 8 "Reserved" 7 "Reserved" 6 "Reserved" 5 "Reserved" 4 "TrackStoppedFromOncoming" 3 "TrackOncoming" 2 "TrackMoving" 1 "TrackStopppedFromMoving" 0 "Stationary" ;
VAL_ 1044 Status_11 7 "Reserved" 6 "Coasted" 5 "Updated" 4 "NewUpdated" 3 "NewCoasted" 2 "New" 1 "Merged" 0 "Invalid" ;
VAL_ 1047 DetectionSensor_12 4 "tracklets and vision" 3 "vision only" 2 "multiple tracklets" 1 "single tracklet" 0 "no matched measurements" ;
VAL_ 1046 MC_object_class_12 7 "Bicycle" 6 "Pedestrian" 5 "Special car" 4 "Box Truck" 3 "Bus" 2 "Motorcycle" 1 "Car" 0 "Undetermined" ;
VAL_ 1046 Movement_12 15 "NotAvailable" 14 "Error" 13 "Reserved" 12 "Reserved" 11 "NoTrack" 10 "Reserved" 9 "Reserved" 8 "Reserved" 7 "Reserved" 6 "Reserved" 5 "Reserved" 4 "TrackStoppedFromOncoming" 3 "TrackOncoming" 2 "TrackMoving" 1 "TrackStopppedFromMoving" 0 "Stationary" ;
VAL_ 1046 Status_12 7 "Reserved" 6 "Coasted" 5 "Updated" 4 "NewUpdated" 3 "NewCoasted" 2 "New" 1 "Merged" 0 "Invalid" ;
VAL_ 1049 DetectionSensor_13 4 "tracklets and vision" 3 "vision only" 2 "multiple tracklets" 1 "single tracklet" 0 "no matched measurements" ;
VAL_ 1048 MC_object_class_13 7 "Bicycle" 6 "Pedestrian" 5 "Special car" 4 "Box Truck" 3 "Bus" 2 "Motorcycle" 1 "Car" 0 "Undetermined" ;
VAL_ 1048 Movement_13 15 "NotAvailable" 14 "Error" 13 "Reserved" 12 "Reserved" 11 "NoTrack" 10 "Reserved" 9 "Reserved" 8 "Reserved" 7 "Reserved" 6 "Reserved" 5 "Reserved" 4 "TrackStoppedFromOncoming" 3 "TrackOncoming" 2 "TrackMoving" 1 "TrackStopppedFromMoving" 0 "Stationary" ;
VAL_ 1048 Status_13 7 "Reserved" 6 "Coasted" 5 "Updated" 4 "NewUpdated" 3 "NewCoasted" 2 "New" 1 "Merged" 0 "Invalid" ;
VAL_ 1051 DetectionSensor_14 4 "tracklets and vision" 3 "vision only" 2 "multiple tracklets" 1 "single tracklet" 0 "no matched measurements" ;
VAL_ 1050 MC_object_class_14 7 "Bicycle" 6 "Pedestrian" 5 "Special car" 4 "Box Truck" 3 "Bus" 2 "Motorcycle" 1 "Car" 0 "Undetermined" ;
VAL_ 1050 Movement_14 15 "NotAvailable" 14 "Error" 13 "Reserved" 12 "Reserved" 11 "NoTrack" 10 "Reserved" 9 "Reserved" 8 "Reserved" 7 "Reserved" 6 "Reserved" 5 "Reserved" 4 "TrackStoppedFromOncoming" 3 "TrackOncoming" 2 "TrackMoving" 1 "TrackStopppedFromMoving" 0 "Stationary" ;
VAL_ 1050 Status_14 7 "Reserved" 6 "Coasted" 5 "Updated" 4 "NewUpdated" 3 "NewCoasted" 2 "New" 1 "Merged" 0 "Invalid" ;
VAL_ 1053 DetectionSensor_15 4 "tracklets and vision" 3 "vision only" 2 "multiple tracklets" 1 "single tracklet" 0 "no matched measurements" ;
VAL_ 1052 MC_object_class_15 7 "Bicycle" 6 "Pedestrian" 5 "Special car" 4 "Box Truck" 3 "Bus" 2 "Motorcycle" 1 "Car" 0 "Undetermined" ;
VAL_ 1052 Movement_15 15 "NotAvailable" 14 "Error" 13 "Reserved" 12 "Reserved" 11 "NoTrack" 10 "Reserved" 9 "Reserved" 8 "Reserved" 7 "Reserved" 6 "Reserved" 5 "Reserved" 4 "TrackStoppedFromOncoming" 3 "TrackOncoming" 2 "TrackMoving" 1 "TrackStopppedFromMoving" 0 "Stationary" ;
VAL_ 1052 Status_15 7 "Reserved" 6 "Coasted" 5 "Updated" 4 "NewUpdated" 3 "NewCoasted" 2 "New" 1 "Merged" 0 "Invalid" ;
VAL_ 1055 DetectionSensor_16 4 "tracklets and vision" 3 "vision only" 2 "multiple tracklets" 1 "single tracklet" 0 "no matched measurements" ;
VAL_ 1054 MC_object_class_16 7 "Bicycle" 6 "Pedestrian" 5 "Special car" 4 "Box Truck" 3 "Bus" 2 "Motorcycle" 1 "Car" 0 "Undetermined" ;
VAL_ 1054 Movement_16 15 "NotAvailable" 14 "Error" 13 "Reserved" 12 "Reserved" 11 "NoTrack" 10 "Reserved" 9 "Reserved" 8 "Reserved" 7 "Reserved" 6 "Reserved" 5 "Reserved" 4 "TrackStoppedFromOncoming" 3 "TrackOncoming" 2 "TrackMoving" 1 "TrackStopppedFromMoving" 0 "Stationary" ;
VAL_ 1054 Status_16 7 "Reserved" 6 "Coasted" 5 "Updated" 4 "NewUpdated" 3 "NewCoasted" 2 "New" 1 "Merged" 0 "Invalid" ;
VAL_ 1901 FCW 1 "FCW On" 0 "FCW Off" ;
VAL_ 1901 TargetVehicle_Type 5 "Special Car" 4 "truck" 3 "bus" 2 "minibus" 1 "car" 0 "no vehicle" ;
VAL_ 1904 AdditionVehicle1_Type 5 "Special Car" 4 "truck" 3 "bus" 2 "minibus" 1 "car" 0 "No Vehicle" ;
VAL_ 1904 AdditionVehicle2_Type 5 "Special Car" 4 "truck" 3 "bus" 2 "minibus" 1 "car" 0 "No Vehicle" ;
VAL_ 1905 AdditionVehicle3_Type 5 "Special Car" 4 "truck" 3 "Bus" 2 "minibus" 1 "car" 0 "No Vehicle" ;
VAL_ 1905 AdditionVehicle4_Type 5 "Special Car" 4 "truck" 3 "bus" 2 "minibus" 1 "car" 0 "No Vehicle" ;
VAL_ 1906 AdditionVehicle5_Type 5 "Special Car" 4 "truck" 3 "bus" 2 "minibus" 1 "car" 0 "No Vehicle" ;
VAL_ 1906 AdditionVehicle6_Type 5 "Special Car" 4 "truck" 3 "bus" 2 "minibus" 1 "car" 0 "No Vehicle" ;
VAL_ 1907 AdditionVehicle7_Type 5 "Special Car" 4 "truck" 3 "bus" 2 "minibus" 1 "car" 0 "No Vehicle" ;
VAL_ 1907 AdditionVehicle8_Type 5 "Special Car" 4 "truck" 3 "bus" 2 "minibus" 1 "car" 0 "No Vehicle" ;
VAL_ 1908 AdditionVehicle9_Type 5 "Special Car" 4 "truck" 3 "bus" 2 "minibus" 1 "car" 0 "No Vehicle" ;
VAL_ 1908 AdditionVehicle10_Type 5 "Special Car" 4 "truck" 3 "Bus" 2 "minibus" 1 "car" 0 "No Vehicle" ;
VAL_ 1909 AdditionVehicle11_Type 5 "Special Car" 4 "truck" 3 "bus" 2 "minibus" 1 "car" 0 "No Vehicle" ;
VAL_ 1909 AdditionVehicle12_Type 5 "Special Car" 4 "truck" 3 "bus" 2 "minibus" 1 "car" 0 "No Vehicle" ;
VAL_ 1910 AdditionVehicle13_Type 5 "Special Car" 4 "truck" 3 "bus" 2 "minibus" 1 "car" 0 "No Vehicle" ;
VAL_ 1910 AdditionVehicle14_Type 5 "Special Car" 4 "truck" 3 "bus" 2 "minibus" 1 "car" 0 "No Vehicle" ;
VAL_ 1911 AdditionVehicle15_Type 5 "Special Car" 4 "truck" 3 "bus" 2 "minibus" 1 "car" 0 "No Vehicle" ;
VAL_ 1911 AdditionVehicle16_Type 5 "Special Car" 4 "truck" 3 "bus" 2 "minibus" 1 "car" 0 "No Vehicle" ;
VAL_ 1520 Lane1_Type 15 "Invalid" 6 "Barrier" 5 "Bott'sDots" 4 "DoubleLane" 3 "Dashed" 2 "RoadEdge" 1 "Solid" 0 "Undecided" ;
VAL_ 1520 Lane1_Quality 3 "High" 2 "Medium" 1 "Low" 0 "Unknown" ;
VAL_ 1521 Lane1_LineCrossing 1 "Line crossing" 0 "No line cross" ;
VAL_ 1521 Lane1_LineMarkColor 1 "Yellow" 0 "White" ;
VAL_ 1522 Lane2_Type 15 "Invalid" 6 "Barrier" 5 "Bott'sDots" 4 "DoubleLane" 3 "Dashed" 2 "RoadEdge" 1 "Solid" 0 "Undecided" ;
VAL_ 1522 Lane2_Quality 3 "High" 2 "Medium" 1 "Low" 0 "Unknown" ;
VAL_ 1523 Lane2_LineCrossing 1 "Line crossing" 0 "No line cross" ;
VAL_ 1523 Lane2_LineMarkColor 1 "Yellow" 0 "White" ;
VAL_ 1524 Lane3_Type 15 "Invalid" 6 "Barrier" 5 "Bott'sDots" 4 "DoubleLane" 3 "Dashed" 2 "RoadEdge" 1 "Solid" 0 "Undecided" ;
VAL_ 1524 Lane3_Quality 3 "High" 2 "Medium" 1 "Low" 0 "Unknown" ;
VAL_ 1525 Lane3_LineCrossing 1 "Line crossing" 0 "No line cross" ;
VAL_ 1525 Lane3_LineMarkColor 1 "Yellow" 0 "White" ;
VAL_ 1526 Lane4_Type 15 "Invalid" 6 "Barrier" 5 "Bott'sDots" 4 "DoubleLane" 3 "Dashed" 2 "RoadEdge" 1 "Solid" 0 "Undecided" ;
VAL_ 1526 Lane4_Quality 3 "High" 2 "Medium" 1 "Low" 0 "Unknown" ;
VAL_ 1527 Lane4_LineCrossing 1 "Line crossing" 0 "No line cross" ;
VAL_ 1527 Lane4_LineMarkColor 1 "Yellow" 0 "White" ;
VAL_ 1914 TargetPedestrian_Type 3 "Pedestrian" 4 "Bicycle" ;
VAL_ 1915 TargetPedestrian1_Type 3 "Pedestrian" 4 "Bicycle" ;
VAL_ 1915 TargetPedestrian2_Type 3 "Pedestrian" 4 "Bicycle" ;
VAL_ 1916 TargetPedestrian3_Type 3 "Pedestrian" 4 "Bicycle" ;
VAL_ 1916 TargetPedestrian4_Type 3 "Pedestrian" 4 "Bicycle" ;
VAL_ 1917 TargetPedestrian5_Type 3 "Pedestrian" 4 "Bicycle" ;
VAL_ 1917 TargetPedestrian6_Type 3 "Pedestrian" 4 "Bicycle" ;
VAL_ 1890 Can_Msg1_Ender 1 "finish" 0 "no finish" ;
VAL_ 1891 Can_Msg2_Ender 1 "finish" 0 "no finish" ;
VAL_ 1892 Can_Msg3_Ender 1 "finish" 0 "no finish" ;
VAL_ 1792 Sound_type 7 "Stop&Go" 6 "FCW+PCW" 5 "UFCW" 4 "TSR" 3 "HW" 2 "LDW Right" 1 "LDW Left" 0 "silent" ;
VAL_ 1792 Time_Indicator 1 "night" 0 "day" ;
VAL_ 1792 ZeroSpeed 1 "stop" 0 "run" ;
VAL_ 1792 HMW_valid 1 "on" 0 "off" ;
VAL_ 1792 LDWoff 1 "disable" 0 "enable" ;
VAL_ 1792 LeftLDWon 1 "warning" 0 "no warning" ;
VAL_ 1792 RightLDWon 1 "warning" 0 "no warning" ;
VAL_ 1792 FCW_on 1 "warning" 0 "no warning" ;
VAL_ 1792 PedsFCW 1 "warning" 0 "no warning" ;
VAL_ 1792 PedInDZ 1 "ped in DZ" 0 "no ped in DZ" ;
VAL_ 1792 TSR_enabled 1 "on" 0 "off" ;
VAL_ 1792 TSR_Level 7 "30-35kmh" 6 "25-30kmh" 5 "20-25kmh" 4 "15-20kmh" 3 "10-15kmh" 2 "5-10kmh" 1 "0-5kmh" 0 "save" ;
VAL_ 1792 HMW_Level 3 "HW <=0.6" 2 "HW <=HW Config" 1 "HWM > HW Config" 0 "no car" ;
